VERSION ""

NS_ :

BS_:

BU_: GW LAS

BO_ 459 GW_1CB: 16 GW
 SG_ IBCU_RollingCounter_1CB : 51|4@0+ (1,0) [0|15] "" Vector__XXX
 SG_ IBCU_CRCCheck_1CB : 63|8@0+ (1,0) [0|255] "" Vector__XXX
 SG_ IBCU_CRCCheck_237 : 127|8@0+ (1,0) [0|255] "" Vector__XXX
 SG_ IBCU_RollingCounter_237 : 115|4@0+ (1,0) [0|15] "" Vector__XXX
 SG_ IBCU_BrakePedalApplied : 90|1@0+ (1,0) [0|1] ""  LAS

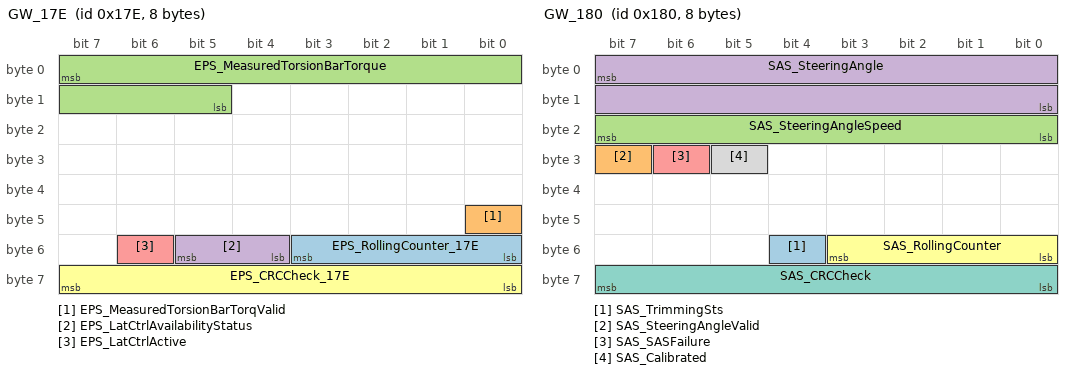
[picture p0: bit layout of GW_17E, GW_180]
BO_ 382 GW_17E: 8 GW
 SG_ EPS_RollingCounter_17E : 51|4@0+ (1,0) [0|15] ""  LAS
 SG_ EPS_MeasuredTorsionBarTorqValid : 40|1@0+ (1,0) [0|1] ""  LAS
 SG_ EPS_MeasuredTorsionBarTorque : 7|11@0+ (0.01,-10.23) [-10.23|10.23] "Nm"  LAS
 SG_ EPS_LatCtrlAvailabilityStatus : 53|2@0+ (1,0) [0|3] ""  LAS
 SG_ EPS_LatCtrlActive : 54|1@0+ (1,0) [0|1] ""  LAS
 SG_ EPS_CRCCheck_17E : 63|8@0+ (1,0) [0|255] ""  LAS

BO_ 384 GW_180: 8 GW
 SG_ SAS_TrimmingSts : 52|1@0+ (1,0) [0|1] ""  LAS
 SG_ SAS_SteeringAngleValid : 31|1@0+ (1,0) [0|1] ""  LAS
 SG_ SAS_SteeringAngleSpeed : 23|8@0+ (4,0) [0|1016] "deg/s"  LAS
 SG_ SAS_SteeringAngle : 7|16@0- (0.1,0) [-780|780] "degree"  LAS
 SG_ SAS_SASFailure : 30|1@0+ (1,0) [0|1] ""  LAS
 SG_ SAS_RollingCounter : 51|4@0+ (1,0) [0|15] ""  LAS
 SG_ SAS_CRCCheck : 63|8@0+ (1,0) [0|255] ""  LAS
 SG_ SAS_Calibrated : 29|1@0+ (1,0) [0|1] ""  LAS

BO_ 391 EPBi_187: 48 GW
 SG_ ESP_VehicleSpeedValid : 37|1@0+ (1,0) [0|1] ""  LAS
 SG_ ESP_VehicleSpeed : 36|13@0+ (0.05625,0) [0|360] "km/h"  LAS
 SG_ ESP_TCSFailStatus : 4|1@0+ (1,0) [0|1] ""  LAS
 SG_ ESP_RollingCounter_187 : 51|4@0+ (1,0) [0|15] ""  LAS
 SG_ ESP_ESPFunctionStatus : 1|1@0+ (1,0) [0|1] ""  LAS
 SG_ ESP_ESPActiveStatus : 0|1@0+ (1,0) [0|1] ""  LAS
 SG_ ESP_CRCCheck_187 : 63|8@0+ (1,0) [0|255] ""  LAS
 SG_ ESP_ABSFailStatus : 3|1@0+ (1,0) [0|1] ""  LAS

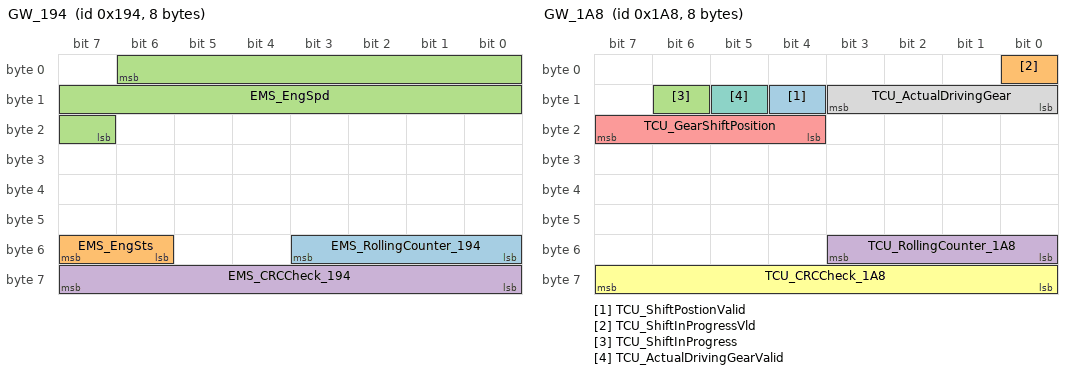
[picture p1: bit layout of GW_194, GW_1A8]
BO_ 404 GW_194: 8 GW
 SG_ EMS_RollingCounter_194 : 51|4@0+ (1,0) [0|15] ""  LAS
 SG_ EMS_EngSts : 55|2@0+ (1,0) [0|3] ""  LAS
 SG_ EMS_EngSpd : 6|16@0+ (0.25,0) [0|16383.5] "Rpm"  LAS
 SG_ EMS_CRCCheck_194 : 63|8@0+ (1,0) [0|255] ""  LAS

BO_ 422 GW_1A6: 8 GW
 SG_ PCU_PwrTrainSts : 55|2@0+ (1,0) [0|3] ""  LAS
 SG_ PCU_AccPedl : 47|8@0+ (0.392,0) [0|99.96] "pct"  LAS

BO_ 424 GW_1A8: 8 GW
 SG_ TCU_ShiftPostionValid : 12|1@0+ (1,0) [0|1] ""  LAS
 SG_ TCU_ShiftInProgressVld : 0|1@0+ (1,0) [0|1] ""  LAS
 SG_ TCU_ShiftInProgress : 14|1@0+ (1,0) [0|1] ""  LAS
 SG_ TCU_RollingCounter_1A8 : 51|4@0+ (1,0) [0|15] ""  LAS
 SG_ TCU_GearShiftPosition : 23|4@0+ (1,0) [0|15] ""  LAS
 SG_ TCU_CRCCheck_1A8 : 63|8@0+ (1,0) [0|255] ""  LAS
 SG_ TCU_ActualDrivingGearValid : 13|1@0+ (1,0) [0|1] ""  LAS
 SG_ TCU_ActualDrivingGear : 11|4@0+ (1,0) [0|15] ""  LAS

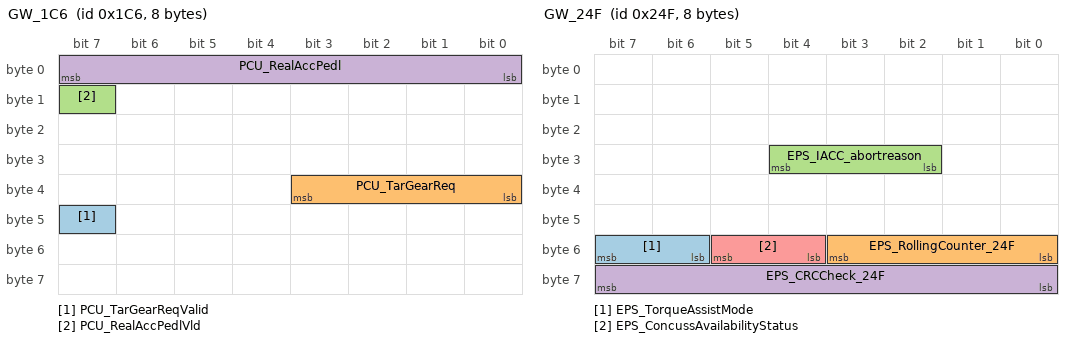
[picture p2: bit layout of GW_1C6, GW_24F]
BO_ 454 GW_1C6: 8 GW
 SG_ PCU_TarGearReqValid : 47|1@0+ (1,0) [0|1] ""  LAS
 SG_ PCU_TarGearReq : 35|4@0+ (1,0) [0|15] ""  LAS
 SG_ PCU_RealAccPedlVld : 15|1@0+ (1,0) [0|1] ""  LAS
 SG_ PCU_RealAccPedl : 7|8@0+ (0.392,0) [0|99.96] "%"  LAS

BO_ 518 EPBi_206: 48 GW
 SG_ ESP_CRCCheck_277 : 319|8@0+ (1,0) [0|255] "" Vector__XXX
 SG_ ESP_RollingCounter_277 : 307|4@0+ (1,0) [0|15] "" Vector__XXX
 SG_ Wheel_Speed_RR_Valid_Data : 71|1@0+ (1,0) [0|1] ""  LAS
 SG_ Wheel_Speed_RR_Pulse : 231|8@0+ (1,0) [0|254] ""  LAS
 SG_ Wheel_Speed_RR_Direction : 70|2@0+ (1,0) [0|3] ""  LAS
 SG_ Wheel_Speed_RR_Data : 68|13@0+ (0.05625,0) [0|360] "km/h"  LAS
 SG_ Wheel_Speed_RL_Valid_Data : 87|1@0+ (1,0) [0|1] ""  LAS
 SG_ Wheel_Speed_RL_Pulse : 239|8@0+ (1,0) [0|254] ""  LAS
 SG_ Wheel_Speed_RL_Direction : 86|2@0+ (1,0) [0|3] ""  LAS
 SG_ Wheel_Speed_RL_Data : 84|13@0+ (0.05625,0) [0|360] "km/h"  LAS
 SG_ Wheel_Speed_FR_Valid_Data : 7|1@0+ (1,0) [0|1] ""  LAS
 SG_ Wheel_Speed_FR_Pulse : 223|8@0+ (1,0) [0|254] ""  LAS
 SG_ Wheel_Speed_FR_Direction : 6|2@0+ (1,0) [0|3] ""  LAS
 SG_ Wheel_Speed_FR_Data : 4|13@0+ (0.05625,0) [0|360] "km/h"  LAS
 SG_ Wheel_Speed_FL_Valid_Data : 23|1@0+ (1,0) [0|1] ""  LAS
 SG_ Wheel_Speed_FL_Pulse : 215|8@0+ (1,0) [0|254] ""  LAS
 SG_ Wheel_Speed_FL_Direction : 22|2@0+ (1,0) [0|3] ""  LAS
 SG_ Wheel_Speed_FL_Data : 20|13@0+ (0.05625,0) [0|360] "km/h"  LAS
 SG_ ESP_YawRateValid : 375|1@0+ (1,0) [0|1] ""  LAS
 SG_ ESP_YawRate : 357|14@0+ (0.01,-81.91) [-81.91|81.91] "degree/s"  LAS
 SG_ ESP_VehicleStandstill : 267|1@0+ (1,0) [0|1] ""  LAS
 SG_ ESP_VDCActive : 266|1@0+ (1,0) [0|1] ""  LAS
 SG_ ESP_TCSActive : 265|1@0+ (1,0) [0|1] ""  LAS
 SG_ ESP_RollingCounter_278 : 371|4@0+ (1,0) [0|15] ""  LAS
 SG_ ESP_RollingCounter_258 : 243|4@0+ (1,0) [0|15] ""  LAS
 SG_ ESP_RollingCounter_208 : 115|4@0+ (1,0) [0|15] ""  LAS
 SG_ ESP_RollingCounter_206 : 51|4@0+ (1,0) [0|15] ""  LAS
 SG_ ESP_PrefillAvailable : 259|1@0+ (1,0) [0|1] ""  LAS
 SG_ ESP_PrefillActive : 260|1@0+ (1,0) [0|1] ""  LAS
 SG_ ESP_OnlyABSActive : 264|1@0+ (1,0) [0|1] ""  LAS
 SG_ ESP_MasCylBrakePressureValid : 199|1@0+ (1,0) [0|1] ""  LAS
 SG_ ESP_MasCylBrakePressure : 195|12@0+ (0.1,0) [0|250] "Bar"  LAS
 SG_ ESP_LongAccel : 351|10@0+ (0.03125,-16) [-16|15.90625] "m/s2"  LAS
 SG_ ESP_LatAccel : 343|8@0+ (0.1,-12.7) [-12.7|12.7] "m/s2"  LAS
 SG_ ESP_HDC_STATUS : 274|2@0+ (1,0) [0|3] ""  LAS
 SG_ ESP_CRCCheck_278 : 383|8@0+ (1,0) [0|255] ""  LAS
 SG_ ESP_CRCCheck_258 : 255|8@0+ (1,0) [0|255] ""  LAS
 SG_ ESP_CRCCheck_208 : 127|8@0+ (1,0) [0|255] ""  LAS
 SG_ ESP_CRCCheck_206 : 63|8@0+ (1,0) [0|255] ""  LAS
 SG_ ESP_BrakeForce : 263|1@0+ (1,0) [0|1] ""  LAS
 SG_ ESP_AWBavailable : 271|1@0+ (1,0) [0|1] ""  LAS
 SG_ ESP_AWBactive : 256|1@0+ (1,0) [0|1] ""  LAS
 SG_ ESP_AEBdecActive : 257|1@0+ (1,0) [0|1] ""  LAS
 SG_ ESP_AEBAvailable : 258|1@0+ (1,0) [0|1] ""  LAS
 SG_ ESP_ABAavailable : 261|1@0+ (1,0) [0|1] ""  LAS
 SG_ ESP_ABAactive : 262|1@0+ (1,0) [0|1] ""  LAS

BO_ 583 APA_247: 32 GW
 SG_ APA_APAOnOff : 6|1@0+ (1,0) [0|1] ""  LAS

BO_ 591 GW_24F: 8 GW
 SG_ EPS_TorqueAssistMode : 55|2@0+ (1,0) [0|3] ""  LAS
 SG_ EPS_RollingCounter_24F : 51|4@0+ (1,0) [0|15] ""  LAS
 SG_ EPS_IACC_abortreason : 28|3@0+ (1,0) [0|7] ""  LAS
 SG_ EPS_CRCCheck_24F : 63|8@0+ (1,0) [0|255] ""  LAS
 SG_ EPS_ConcussAvailabilityStatus : 53|2@0+ (1,0) [0|3] ""  LAS

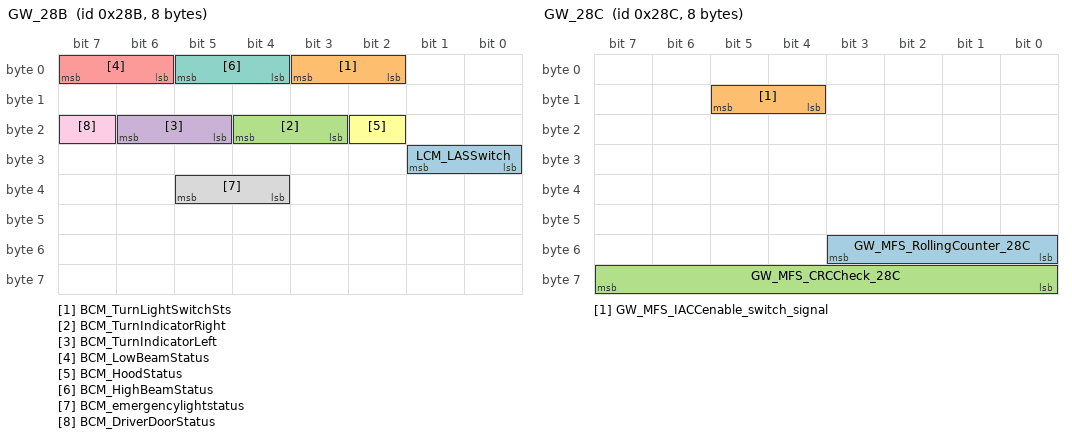
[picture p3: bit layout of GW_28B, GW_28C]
BO_ 651 GW_28B: 8 GW
 SG_ LCM_LASSwitch : 25|2@0+ (1,0) [0|3] ""  LAS
 SG_ BCM_TurnLightSwitchSts : 3|2@0+ (1,0) [0|3] ""  LAS
 SG_ BCM_TurnIndicatorRight : 20|2@0+ (1,0) [0|3] ""  LAS
 SG_ BCM_TurnIndicatorLeft : 22|2@0+ (1,0) [0|3] ""  LAS
 SG_ BCM_LowBeamStatus : 7|2@0+ (1,0) [0|3] ""  LAS
 SG_ BCM_HoodStatus : 18|1@0+ (1,0) [0|1] ""  LAS
 SG_ BCM_HighBeamStatus : 5|2@0+ (1,0) [0|3] ""  LAS
 SG_ BCM_emergencylightstatus : 37|2@0+ (1,0) [0|3] ""  LAS
 SG_ BCM_DriverDoorStatus : 23|1@0+ (1,0) [0|1] ""  LAS

BO_ 652 GW_28C: 8 GW
 SG_ GW_MFS_RollingCounter_28C : 51|4@0+ (1,0) [0|15] ""  LAS
 SG_ GW_MFS_IACCenable_switch_signal : 13|2@0+ (1,0) [0|3] ""  LAS
 SG_ GW_MFS_CRCCheck_28C : 63|8@0+ (1,0) [0|255] ""  LAS

BO_ 676 LCDAR_2A4: 64 GW
 SG_ LCDAR_RollingCounter_2AF : 51|4@0+ (1,0) [0|15] ""  LAS
 SG_ LCDAR_Left_ELK_oAlert : 29|2@0+ (1,0) [0|3] ""  LAS
 SG_ LCDAR_ELK_oStatus : 27|2@0+ (1,0) [0|3] ""  LAS
 SG_ LCDAR_ELK_oAlert : 25|2@0+ (1,0) [0|3] ""  LAS
 SG_ LCDAR_CRCCheck_2AF : 63|8@0+ (1,0) [0|255] ""  LAS

BO_ 832 GW_340: 8 GW
 SG_ AC_FrBlowType : 2|3@0+ (1,0) [0|7] ""  LAS

BO_ 866 GW_362: 8 GW
 SG_ PCU_DrvMod : 21|3@0+ (1,0) [0|7] ""  LAS

BO_ 870 GW_366: 8 GW
 SG_ AC_EnvironmentalTempVD : 8|1@0+ (1,0) [0|1] ""  LAS
 SG_ AC_EnvironmentalTemp : 23|8@0+ (0.5,-40) [-40|87] "degreeC"  LAS

BO_ 903 GW_387: 8 GW
 SG_ BCM_RainfallLevel : 19|4@0+ (1,0) [0|15] ""  LAS
 SG_ BCM_FrontWiperStatus : 25|2@0+ (1,0) [0|3] ""  LAS

BO_ 912 GW_390: 8 GW
 SG_ BCM_SOH_LifePercent : 15|8@0+ (1,0) [0|100] "%"  LAS
 SG_ BCM_PMSLevel : 5|3@0+ (1,0) [0|7] ""  LAS

BO_ 916 GW_394: 8 GW
 SG_ HU_TLAEnable : 9|2@0+ (1,0) [0|3] ""  LAS
 SG_ HU_ELKEnable : 1|2@0+ (1,0) [0|3] ""  LAS

BO_ 922 LAS_39A: 32 LAS
 SG_ LAS_TSRWarningSign : 83|4@0+ (1,0) [0|15] "" Vector__XXX
 SG_ LAS_TSRStatus : 26|3@0+ (1,0) [0|7] "" Vector__XXX
 SG_ LAS_TSRRightLaneStatus : 55|3@0+ (1,0) [0|7] "" Vector__XXX
 SG_ LAS_TSRRightLaneSpdLimit : 143|8@0+ (1,0) [0|255] "" Vector__XXX
 SG_ LAS_TSRProhibitionSign : 66|5@0+ (1,0) [0|31] "" Vector__XXX
 SG_ LAS_TSRMandatorySign : 70|4@0+ (1,0) [0|15] "" Vector__XXX
 SG_ LAS_TSRLeftLaneStatus : 47|3@0+ (1,0) [0|7] "" Vector__XXX
 SG_ LAS_TSRLeftLaneSpdLimit : 135|8@0+ (1,0) [0|255] "" Vector__XXX
 SG_ LAS_TSRHostSpdLimitUnits : 41|2@0+ (1,0) [0|3] "" Vector__XXX
 SG_ LAS_TSRHostSpdLimit : 39|8@0+ (1,0) [0|255] "" Vector__XXX
 SG_ LAS_TSREnable : 30|1@0+ (1,0) [0|1] "" Vector__XXX
 SG_ LAS_TLAWarninglevel : 197|2@0+ (1,0) [0|3] "" Vector__XXX
 SG_ LAS_TLAStopLine_HostLane : 111|8@0+ (1,0) [0|255] "" Vector__XXX
 SG_ LAS_TLAStatus : 193|2@0+ (1,0) [0|3] "" Vector__XXX
 SG_ LAS_TLAObjectType_RightLane : 239|3@0+ (1,0) [0|7] "" Vector__XXX
 SG_ LAS_TLAObjectType_LeftLane : 219|3@0+ (1,0) [0|7] "" Vector__XXX
 SG_ LAS_TLAObjectType_HostLane : 212|3@0+ (1,0) [0|7] "" Vector__XXX
 SG_ LAS_TLAObjectStatus_RightLane : 247|2@0+ (1,0) [0|3] "" Vector__XXX
 SG_ LAS_TLAObjectStatus_LeftLane : 245|2@0+ (1,0) [0|3] "" Vector__XXX
 SG_ LAS_TLAObjectStatus_HostLane : 199|2@0+ (1,0) [0|3] "" Vector__XXX
 SG_ LAS_TLAObjectDetection_RightLane : 227|1@0+ (1,0) [0|1] "" Vector__XXX
 SG_ LAS_TLAObjectDetection_LeftLane : 223|1@0+ (1,0) [0|1] "" Vector__XXX
 SG_ LAS_TLAObjectDetection_HostLane : 200|1@0+ (1,0) [0|1] "" Vector__XXX
 SG_ LAS_TLAObjectColour_RightLane : 225|2@0+ (1,0) [0|3] "" Vector__XXX
 SG_ LAS_TLAObjectColour_LeftLane : 221|2@0+ (1,0) [0|3] "" Vector__XXX
 SG_ LAS_TLAObjectColour_HostLane : 204|2@0+ (1,0) [0|3] "" Vector__XXX
 SG_ LAS_TLAEnable : 194|1@0+ (1,0) [0|1] "" Vector__XXX
 SG_ LAS_TLADistance_HostLane : 103|8@0+ (1,0) [0|255] "" Vector__XXX
 SG_ LAS_TLACountDownTime_HostLane : 94|7@0+ (1,0) [0|127] "" Vector__XXX
 SG_ LAS_TLAArrowDirection_RightLane : 236|3@0+ (1,0) [0|7] "" Vector__XXX
 SG_ LAS_TLAArrowDirection_LeftLane : 216|3@0+ (1,0) [0|7] "" Vector__XXX
 SG_ LAS_TLAArrowDirection_HostLane : 215|3@0+ (1,0) [0|7] "" Vector__XXX
 SG_ LAS_RollingCounter_3D4 : 115|4@0+ (1,0) [0|15] "" Vector__XXX
 SG_ LAS_RollingCounter_3C0 : 179|4@0+ (1,0) [0|15] "" Vector__XXX
 SG_ LAS_RollingCounter_37D : 243|4@0+ (1,0) [0|15] "" Vector__XXX
 SG_ LAS_RollingCounter_332 : 51|4@0+ (1,0) [0|15] "" Vector__XXX
 SG_ LAS_OverspeedWarningOffset : 14|5@0+ (1,-10) [-10|10] "km/h" Vector__XXX
 SG_ LAS_OverspeedWarningEnableStatus : 15|1@0+ (1,0) [0|1] "" Vector__XXX
 SG_ LAS_OverspeedVisualWarning : 5|1@0+ (1,0) [0|1] "" Vector__XXX
 SG_ LAS_OverspeedSoundWarningEnSt : 27|1@0+ (1,0) [0|1] "" Vector__XXX
 SG_ LAS_OverspeedSoundWarning : 2|1@0+ (1,0) [0|1] "" Vector__XXX
 SG_ LAS_HMAStatus : 44|2@0+ (1,0) [0|3] "" Vector__XXX
 SG_ LAS_HMALightDistribution : 8|1@0+ (1,0) [0|1] "" Vector__XXX
 SG_ LAS_HMAEnableStatus : 22|1@0+ (1,0) [0|1] "" Vector__XXX
 SG_ LAS_FrontCameraFailureStatus : 17|2@0+ (1,0) [0|3] "" Vector__XXX
 SG_ LAS_FrontCameraCalibrationStatus : 20|2@0+ (1,0) [0|3] "" Vector__XXX
 SG_ LAS_CRCCheck_3D4 : 127|8@0+ (1,0) [0|255] "" Vector__XXX
 SG_ LAS_CRCCheck_3C0 : 191|8@0+ (1,0) [0|255] "" Vector__XXX
 SG_ LAS_CRCCheck_37D : 255|8@0+ (1,0) [0|255] "" Vector__XXX
 SG_ LAS_CRCCheck_332 : 63|8@0+ (1,0) [0|255] "" Vector__XXX

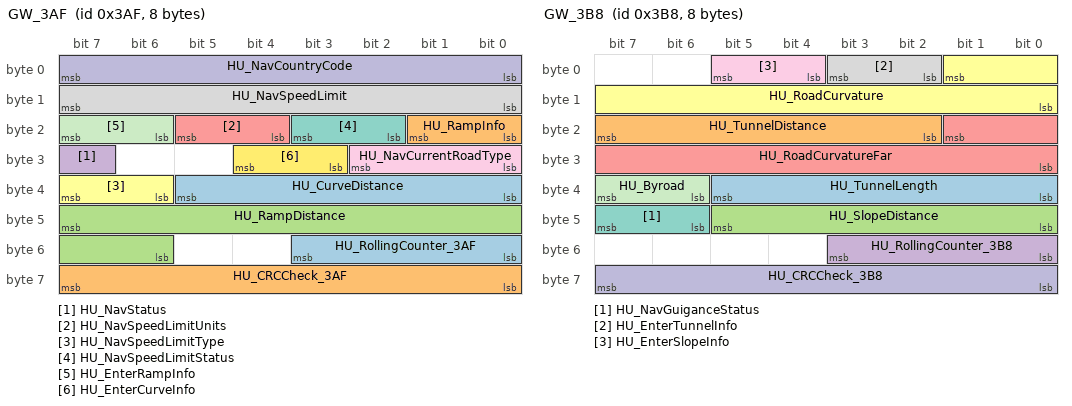
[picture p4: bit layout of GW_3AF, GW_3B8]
BO_ 943 GW_3AF: 8 GW
 SG_ HU_RollingCounter_3AF : 51|4@0+ (1,0) [0|15] ""  LAS
 SG_ HU_RampInfo : 17|2@0+ (1,0) [0|3] ""  LAS
 SG_ HU_RampDistance : 47|10@0+ (10,0) [0|3000] "m"  LAS
 SG_ HU_NavStatus : 31|1@0+ (1,0) [0|1] ""  LAS
 SG_ HU_NavSpeedLimitUnits : 21|2@0+ (1,0) [0|3] ""  LAS
 SG_ HU_NavSpeedLimitType : 39|2@0+ (1,0) [0|3] ""  LAS
 SG_ HU_NavSpeedLimitStatus : 19|2@0+ (1,0) [0|3] ""  LAS
 SG_ HU_NavSpeedLimit : 15|8@0+ (1,0) [0|255] ""  LAS
 SG_ HU_NavCurrentRoadType : 26|3@0+ (1,0) [0|7] ""  LAS
 SG_ HU_NavCountryCode : 7|8@0+ (1,0) [0|255] ""  LAS
 SG_ HU_EnterRampInfo : 23|2@0+ (1,0) [0|3] ""  LAS
 SG_ HU_EnterCurveInfo : 28|2@0+ (1,0) [0|3] ""  LAS
 SG_ HU_CurveDistance : 37|6@0+ (10,0) [0|600] "m"  LAS
 SG_ HU_CRCCheck_3AF : 63|8@0+ (1,0) [0|255] ""  LAS

BO_ 952 GW_3B8: 8 GW
 SG_ HU_TunnelLength : 37|6@0+ (1,0) [0|63] "m"  LAS
 SG_ HU_TunnelDistance : 23|6@0+ (10,0) [0|600] "m"  LAS
 SG_ HU_SlopeDistance : 45|6@0+ (10,0) [0|600] "m"  LAS
 SG_ HU_RollingCounter_3B8 : 51|4@0+ (1,0) [0|15] ""  LAS
 SG_ HU_RoadCurvatureFar : 17|10@0+ (1,0) [0|1023] ""  LAS
 SG_ HU_RoadCurvature : 1|10@0+ (1,0) [0|1023] ""  LAS
 SG_ HU_NavGuiganceStatus : 47|2@0+ (1,0) [0|3] ""  LAS
 SG_ HU_EnterTunnelInfo : 3|2@0+ (1,0) [0|3] ""  LAS
 SG_ HU_EnterSlopeInfo : 5|2@0+ (1,0) [0|3] ""  LAS
 SG_ HU_CRCCheck_3B8 : 63|8@0+ (1,0) [0|255] ""  LAS
 SG_ HU_Byroad : 39|2@0+ (1,0) [0|3] ""  LAS

BO_ 955 GW_3BB: 8 GW
 SG_ HU_SpeedLimitDistance : 5|6@0+ (10,0) [0|600] "m"  LAS

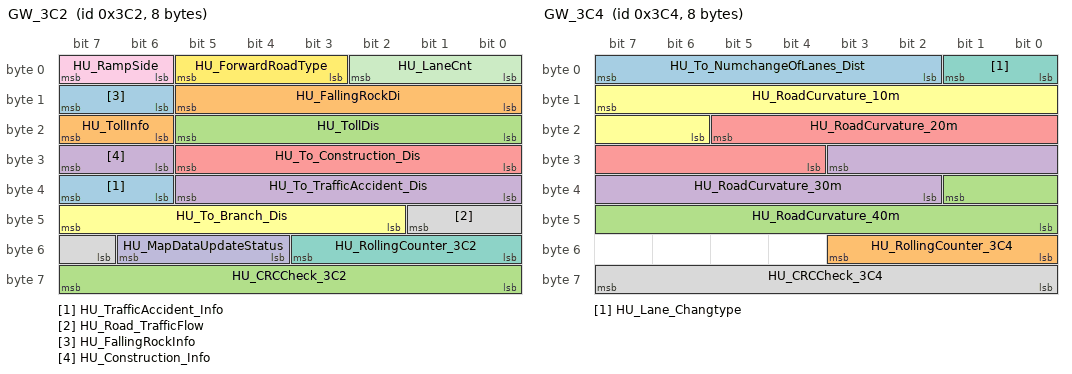
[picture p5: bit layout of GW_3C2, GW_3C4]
BO_ 962 GW_3C2: 8 GW
 SG_ HU_TrafficAccident_Info : 39|2@0+ (1,0) [0|3] ""  LAS
 SG_ HU_TollInfo : 23|2@0+ (1,0) [0|3] ""  LAS
 SG_ HU_TollDis : 21|6@0+ (10,0) [0|600] "m"  LAS
 SG_ HU_To_TrafficAccident_Dis : 37|6@0+ (10,0) [0|600] "m"  LAS
 SG_ HU_To_Construction_Dis : 29|6@0+ (10,0) [0|600] "m"  LAS
 SG_ HU_To_Branch_Dis : 47|6@0+ (10,0) [0|600] "m"  LAS
 SG_ HU_RollingCounter_3C2 : 51|4@0+ (1,0) [0|15] ""  LAS
 SG_ HU_Road_TrafficFlow : 41|3@0+ (1,0) [0|7] ""  LAS
 SG_ HU_RampSide : 7|2@0+ (1,0) [0|3] ""  LAS
 SG_ HU_MapDataUpdateStatus : 54|3@0+ (1,0) [0|7] ""  LAS
 SG_ HU_LaneCnt : 2|3@0+ (1,0) [0|7] ""  LAS
 SG_ HU_ForwardRoadType : 5|3@0+ (1,0) [0|7] ""  LAS
 SG_ HU_FallingRockInfo : 15|2@0+ (1,0) [0|3] ""  LAS
 SG_ HU_FallingRockDi : 13|6@0+ (10,0) [0|600] "m"  LAS
 SG_ HU_CRCCheck_3C2 : 63|8@0+ (1,0) [0|255] ""  LAS
 SG_ HU_Construction_Info : 31|2@0+ (1,0) [0|3] ""  LAS

BO_ 964 GW_3C4: 8 GW
 SG_ HU_To_NumchangeOfLanes_Dist : 7|6@0+ (10,0) [0|600] "m"  LAS
 SG_ HU_RollingCounter_3C4 : 51|4@0+ (1,0) [0|15] ""  LAS
 SG_ HU_RoadCurvature_40m : 33|10@0+ (1,0) [0|1023] "1/m"  LAS
 SG_ HU_RoadCurvature_30m : 27|10@0+ (1,0) [0|1023] "1/m"  LAS
 SG_ HU_RoadCurvature_20m : 21|10@0+ (1,0) [0|1023] "1/m"  LAS
 SG_ HU_RoadCurvature_10m : 15|10@0+ (1,0) [0|1023] "1/m"  LAS
 SG_ HU_Lane_Changtype : 1|2@0+ (1,0) [0|3] ""  LAS
 SG_ HU_CRCCheck_3C4 : 63|8@0+ (1,0) [0|255] ""  LAS

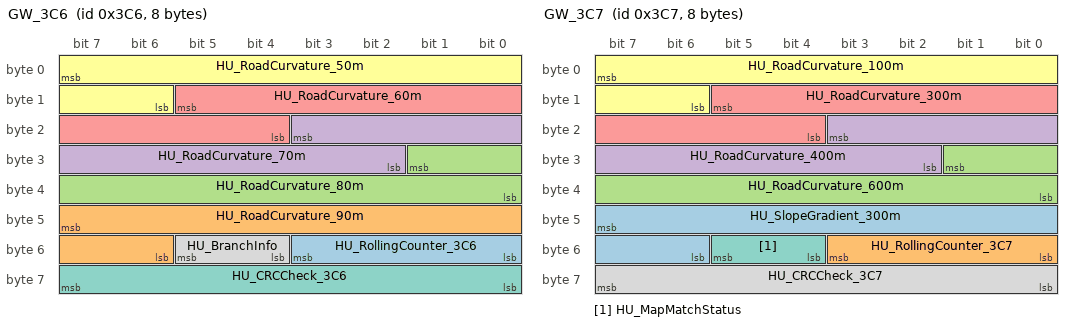
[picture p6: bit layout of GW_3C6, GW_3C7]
BO_ 966 GW_3C6: 8 GW
 SG_ HU_RollingCounter_3C6 : 51|4@0+ (1,0) [0|15] ""  LAS
 SG_ HU_RoadCurvature_90m : 47|10@0+ (1,0) [0|1023] "1/m"  LAS
 SG_ HU_RoadCurvature_80m : 25|10@0+ (1,0) [0|1023] "1/m"  LAS
 SG_ HU_RoadCurvature_70m : 19|10@0+ (1,0) [0|1023] "1/m"  LAS
 SG_ HU_RoadCurvature_60m : 13|10@0+ (1,0) [0|1023] "1/m"  LAS
 SG_ HU_RoadCurvature_50m : 7|10@0+ (1,0) [0|1023] "1/m"  LAS
 SG_ HU_CRCCheck_3C6 : 63|8@0+ (1,0) [0|255] ""  LAS
 SG_ HU_BranchInfo : 53|2@0+ (1,0) [0|3] ""  LAS

BO_ 967 GW_3C7: 8 GW
 SG_ HU_SlopeGradient_300m : 47|10@0+ (0.1,-51.1) [-51.1|51.1] "%"  LAS
 SG_ HU_RollingCounter_3C7 : 51|4@0+ (1,0) [0|15] ""  LAS
 SG_ HU_RoadCurvature_600m : 25|10@0+ (1,0) [0|1023] "1/m"  LAS
 SG_ HU_RoadCurvature_400m : 19|10@0+ (1,0) [0|1023] "1/m"  LAS
 SG_ HU_RoadCurvature_300m : 13|10@0+ (1,0) [0|1023] "1/m"  LAS
 SG_ HU_RoadCurvature_100m : 7|10@0+ (1,0) [0|1023] "1/m"  LAS
 SG_ HU_MapMatchStatus : 53|2@0+ (1,0) [0|3] ""  LAS
 SG_ HU_CRCCheck_3C7 : 63|8@0+ (1,0) [0|255] ""  LAS

BO_ 999 GW_3E7: 8 GW
 SG_ BCM_T_BATT : 39|8@0+ (1,-40) [-40|105] "C"  LAS
 SG_ BCM_Status_Temp : 51|2@0+ (1,0) [0|3] ""  LAS

BO_ 1000 GW_3E8: 8 GW
 SG_ BCM_SOF_Q_STATE : 51|2@0+ (1,0) [0|3] ""  LAS
 SG_ BCM_SOF_Q : 15|8@0+ (0.5,0) [0|127] "Ah"  LAS

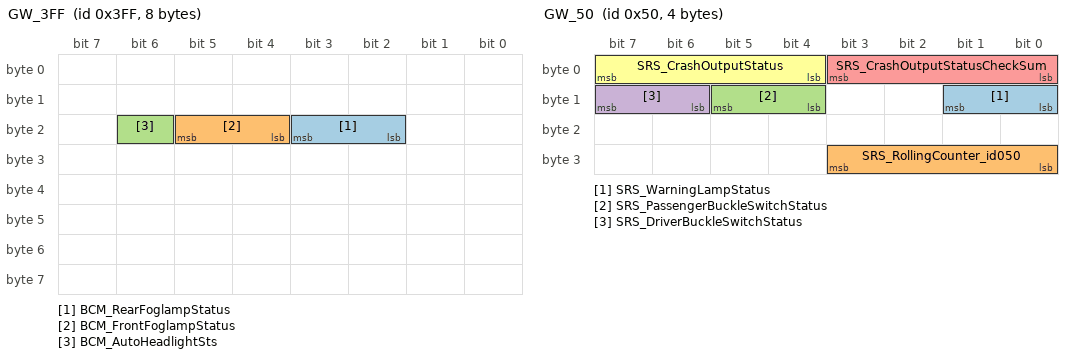
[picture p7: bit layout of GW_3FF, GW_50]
BO_ 1023 GW_3FF: 8 GW
 SG_ BCM_RearFoglampStatus : 19|2@0+ (1,0) [0|3] ""  LAS
 SG_ BCM_FrontFoglampStatus : 21|2@0+ (1,0) [0|3] ""  LAS
 SG_ BCM_AutoHeadlightSts : 22|1@0+ (1,0) [0|1] ""  LAS

BO_ 80 GW_50: 4 GW
 SG_ SRS_WarningLampStatus : 9|2@0+ (1,0) [0|3] ""  LAS
 SG_ SRS_RollingCounter_id050 : 27|4@0+ (1,0) [0|15] ""  LAS
 SG_ SRS_PassengerBuckleSwitchStatus : 13|2@0+ (1,0) [0|3] ""  LAS
 SG_ SRS_DriverBuckleSwitchStatus : 15|2@0+ (1,0) [0|3] ""  LAS
 SG_ SRS_CrashOutputStatusCheckSum : 3|4@0+ (1,0) [0|15] ""  LAS
 SG_ SRS_CrashOutputStatus : 7|4@0+ (1,0) [0|15] ""  LAS

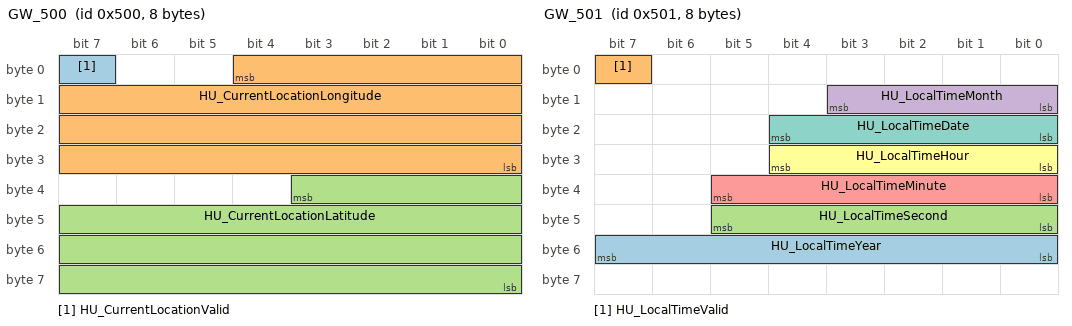
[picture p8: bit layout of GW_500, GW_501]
BO_ 1280 GW_500: 8 GW
 SG_ HU_CurrentLocationValid : 7|1@0+ (1,0) [0|1] ""  LAS
 SG_ HU_CurrentLocationLongitude : 4|29@0+ (1E-006,-268.435455) [-180|180] "degree"  LAS
 SG_ HU_CurrentLocationLatitude : 35|28@0+ (1E-006,-134.217727) [-90|90] "degree"  LAS

BO_ 1281 GW_501: 8 GW
 SG_ HU_LocalTimeYear : 55|8@0+ (1,2013) [2013|2268] "year"  LAS
 SG_ HU_LocalTimeValid : 7|1@0+ (1,0) [0|1] ""  LAS
 SG_ HU_LocalTimeSecond : 45|6@0+ (1,0) [0|59] "second"  LAS
 SG_ HU_LocalTimeMonth : 11|4@0+ (1,0) [1|12] "month"  LAS
 SG_ HU_LocalTimeMinute : 37|6@0+ (1,0) [0|59] "minute"  LAS
 SG_ HU_LocalTimeHour : 28|5@0+ (1,0) [0|23] "hour"  LAS
 SG_ HU_LocalTimeDate : 20|5@0+ (1,0) [1|31] "day"  LAS

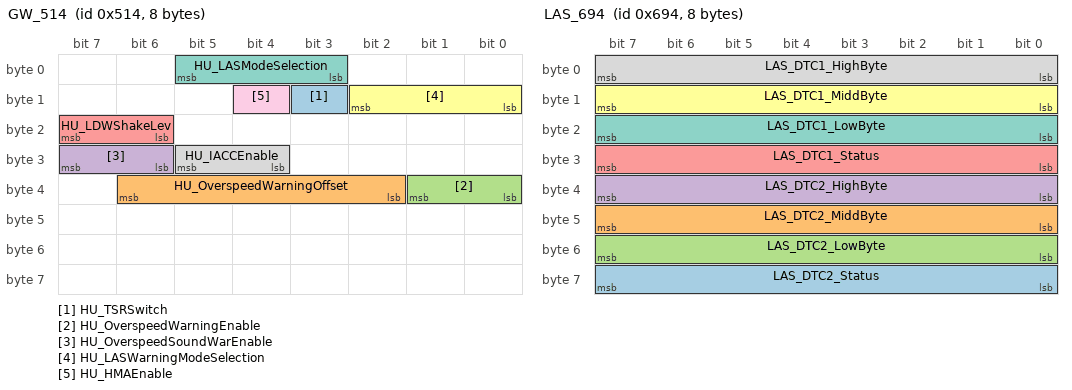
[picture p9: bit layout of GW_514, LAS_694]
BO_ 1300 GW_514: 8 GW
 SG_ HU_TSRSwitch : 11|1@0+ (1,0) [0|1] ""  LAS
 SG_ HU_OverspeedWarningOffset : 38|5@0+ (1,-10) [-10|10] ""  LAS
 SG_ HU_OverspeedWarningEnable : 33|2@0+ (1,0) [0|3] ""  LAS
 SG_ HU_OverspeedSoundWarEnable : 31|2@0+ (1,0) [0|3] ""  LAS
 SG_ HU_LDWShakeLev : 23|2@0+ (1,0) [0|3] ""  LAS
 SG_ HU_LASWarningModeSelection : 10|3@0+ (1,0) [0|7] ""  LAS
 SG_ HU_LASModeSelection : 5|3@0+ (1,0) [0|7] ""  LAS
 SG_ HU_IACCEnable : 29|2@0+ (1,0) [0|3] ""  LAS
 SG_ HU_HMAEnable : 12|1@0+ (1,0) [0|1] ""  LAS

BO_ 1328 GW_530: 8 GW
 SG_ IP_TotalOdometer : 23|24@0+ (0.1,0) [0|999999] "Km"  LAS

BO_ 1684 LAS_694: 8 LAS
 SG_ LAS_DTC2_Status : 63|8@0+ (1,0) [0|255] "" Vector__XXX
 SG_ LAS_DTC2_MiddByte : 47|8@0+ (1,0) [0|255] "" Vector__XXX
 SG_ LAS_DTC2_LowByte : 55|8@0+ (1,0) [0|255] "" Vector__XXX
 SG_ LAS_DTC2_HighByte : 39|8@0+ (1,0) [0|255] "" Vector__XXX
 SG_ LAS_DTC1_Status : 31|8@0+ (1,0) [0|255] "" Vector__XXX
 SG_ LAS_DTC1_MiddByte : 15|8@0+ (1,0) [0|255] "" Vector__XXX
 SG_ LAS_DTC1_LowByte : 23|8@0+ (1,0) [0|255] "" Vector__XXX
 SG_ LAS_DTC1_HighByte : 7|8@0+ (1,0) [0|255] "" Vector__XXX

BO_ 1882 LAS_75A: 64 Vector__XXX

BO_ 1899 LAS_76B: 8 Vector__XXX

CM_ BO_ 459 " ";
CM_ BO_ 382 "L2_EPSCAN , L2_PCAN ";
CM_ SG_ 391 ESP_RollingCounter_187 "AT/DCT ";
CM_ SG_ 391 ESP_CRCCheck_187 "AT/DCT ";
CM_ BO_ 404 " ";
CM_ BO_ 422 " ";
CM_ BO_ 424 " ";
CM_ SG_ 424 TCU_RollingCounter_1A8 "AT/DCT
rollingcounter ";
CM_ SG_ 424 TCU_GearShiftPosition "TCU receives driver demands gear from ESL and make decisition of actual drive mode based on current vehicle/transmission status.
PCU receives this signals to understand actual drive mode and estimate target gear ";
CM_ BO_ 454 " ";
CM_ BO_ 518 "Combined 206,208,23B,258,277,278 ";
CM_ SG_ 518 Wheel_Speed_RR_Pulse "All4wheelpulsesignalsaresentbyABSwithoutfiltering.Theriseedgeandfalledgearebothcountedinit, thewheelpulsemustbesequentialintheway";
CM_ SG_ 518 Wheel_Speed_RL_Pulse "All4wheelpulsesignalsaresentbyABSwithoutfiltering.Theriseedgeandfalledgearebothcountedinit, thewheelpulsemustbesequentialintheway";
CM_ SG_ 518 Wheel_Speed_FR_Pulse "All4wheelpulsesignalsaresentbyABSwithoutfiltering.Theriseedgeandfalledgearebothcountedinit, thewheelpulsemustbesequentialintheway";
CM_ SG_ 518 Wheel_Speed_FL_Pulse "All4wheelpulsesignalsaresentbyABSwithoutfiltering.Theriseedgeandfalledgearebothcountedinit, thewheelpulsemustbesequentialintheway";
CM_ SG_ 518 ESP_RollingCounter_278 "rollingcounter ";
CM_ SG_ 518 ESP_RollingCounter_258 "258 ";
CM_ SG_ 518 ESP_RollingCounter_208 "rollingcounter ";
CM_ SG_ 518 ESP_RollingCounter_206 "rollingcounter ";
CM_ SG_ 518 ESP_MasCylBrakePressureValid "258 ";
CM_ SG_ 518 ESP_CRCCheck_258 "258 ";
CM_ BO_ 583 " ";
CM_ BO_ 651 " ";
CM_ BO_ 652 "MFS_LIN_2 ";
CM_ SG_ 676 LCDAR_RollingCounter_2AF "Rolling counter ";
CM_ BO_ 832 " ";
CM_ BO_ 866 " ";
CM_ BO_ 870 " ";
CM_ BO_ 903 " ";
CM_ BO_ 912 " ";
CM_ BO_ 916 " ";
CM_ SG_ 922 LAS_RollingCounter_3D4 "Rolling counter ";
CM_ SG_ 922 LAS_RollingCounter_3C0 "Rolling counter ";
CM_ SG_ 922 LAS_RollingCounter_37D "Rolling counter ";
CM_ SG_ 922 LAS_RollingCounter_332 "Rolling counter ";
CM_ BO_ 943 " ";
CM_ BO_ 952 " ";
CM_ BO_ 955 " ";
CM_ BO_ 962 " ";
CM_ BO_ 964 " ";
CM_ BO_ 966 " ";
CM_ BO_ 967 " ";
CM_ BO_ 999 " ";
CM_ BO_ 1000 " ";
CM_ BO_ 1023 " ";
CM_ SG_ 80 SRS_PassengerBuckleSwitchStatus "For PDM is configured projects:
(if PDM is configured£¬ logical detection with PDM is required)
0x0= [Buckled] or [Unbuckled and passenger not occupied]
0x1= [Unbuckle and passenger occupied]
0x2= Not Used
0x3= Not Used ";
CM_ BO_ 1280 " ";
CM_ BO_ 1281 " ";
CM_ BO_ 1300 " ";
CM_ BO_ 1328 " ";
CM_ BO_ 1684 " ";
BA_DEF_  "BusType" STRING ;
BA_DEF_ SG_  "GenSigSendType" ENUM  "Cyclic","OnWrite","OnWriteWithRepetition","OnChange","OnChangeWithRepetition","IfActive","IfActiveWithRepetition","NoSigSendType","NotUsed","NotUsed","NotUsed","NotUsed","NotUsed";
BA_DEF_ SG_  "GenSigCycleTime" INT 0 0;
BA_DEF_ SG_  "GenSigInvalidValue" STRING ;
BA_DEF_ SG_  "GenSigStartValue" INT 0 0;
BA_DEF_ BO_  "VFrameFormat" ENUM  "StandardCAN","ExtendedCAN","reserved","reserved","reserved","reserved","reserved","reserved","reserved","reserved","reserved","reserved","reserved","reserved","StandardCAN_FD","ExtendedCAN_FD";
BA_DEF_ BO_  "CANFD_BRS" ENUM  "0","1";
BA_DEF_ BO_  "GenMsgCycleTime" INT 0 65535;
BA_DEF_ BO_  "GenMsgILSupport" ENUM  "No","Yes";
BA_DEF_ BO_  "GenMsgSendType" ENUM  "Cyclic","Event","NotUsed","NotUsed","NotUsed","Cyclic","NotUsed","IfActive","NoMsgSendType","NotUsed";
BA_DEF_ BU_  "ILUsed" ENUM  "No","Yes";
BA_DEF_ BU_  "NodeLayerModules" STRING ;
BA_DEF_DEF_  "BusType" "";
BA_DEF_DEF_  "GenSigSendType" "Cyclic";
BA_DEF_DEF_  "GenSigCycleTime" 0;
BA_DEF_DEF_  "GenSigInvalidValue" "/";
BA_DEF_DEF_  "GenSigStartValue" 0;
BA_DEF_DEF_  "VFrameFormat" "StandardCAN";
BA_DEF_DEF_  "CANFD_BRS" "1";
BA_DEF_DEF_  "GenMsgCycleTime" 0;
BA_DEF_DEF_  "GenMsgILSupport" "Yes";
BA_DEF_DEF_  "GenMsgSendType" "NoMsgSendType";
BA_DEF_DEF_  "ILUsed" "Yes";
BA_DEF_DEF_  "NodeLayerModules" "OSEKNM01.dll,CANoeILNLVector.dll";
BA_ "BusType" "CAN";
BA_ "GenMsgSendType" BO_ 459 0;
BA_ "GenMsgCycleTime" BO_ 459 10;
BA_ "VFrameFormat" BO_ 459 14;
BA_ "GenMsgSendType" BO_ 382 0;
BA_ "GenMsgCycleTime" BO_ 382 10;
BA_ "VFrameFormat" BO_ 382 14;
BA_ "GenMsgSendType" BO_ 384 0;
BA_ "GenMsgCycleTime" BO_ 384 10;
BA_ "VFrameFormat" BO_ 384 14;
BA_ "GenMsgSendType" BO_ 391 0;
BA_ "GenMsgCycleTime" BO_ 391 10;
BA_ "VFrameFormat" BO_ 391 14;
BA_ "GenMsgSendType" BO_ 404 0;
BA_ "GenMsgCycleTime" BO_ 404 10;
BA_ "VFrameFormat" BO_ 404 14;
BA_ "GenMsgSendType" BO_ 422 0;
BA_ "GenMsgCycleTime" BO_ 422 10;
BA_ "VFrameFormat" BO_ 422 14;
BA_ "GenMsgSendType" BO_ 424 0;
BA_ "GenMsgCycleTime" BO_ 424 10;
BA_ "VFrameFormat" BO_ 424 14;
BA_ "GenMsgSendType" BO_ 454 0;
BA_ "GenMsgCycleTime" BO_ 454 10;
BA_ "VFrameFormat" BO_ 454 14;
BA_ "GenMsgSendType" BO_ 518 0;
BA_ "GenMsgCycleTime" BO_ 518 20;
BA_ "VFrameFormat" BO_ 518 14;
BA_ "GenMsgSendType" BO_ 583 0;
BA_ "GenMsgCycleTime" BO_ 583 20;
BA_ "VFrameFormat" BO_ 583 14;
BA_ "GenMsgSendType" BO_ 591 0;
BA_ "GenMsgCycleTime" BO_ 591 20;
BA_ "VFrameFormat" BO_ 591 14;
BA_ "GenMsgSendType" BO_ 651 0;
BA_ "GenMsgCycleTime" BO_ 651 40;
BA_ "VFrameFormat" BO_ 651 14;
BA_ "GenMsgSendType" BO_ 652 0;
BA_ "GenMsgCycleTime" BO_ 652 40;
BA_ "VFrameFormat" BO_ 652 14;
BA_ "GenMsgSendType" BO_ 676 0;
BA_ "GenMsgCycleTime" BO_ 676 50;
BA_ "VFrameFormat" BO_ 676 14;
BA_ "GenMsgSendType" BO_ 832 0;
BA_ "GenMsgCycleTime" BO_ 832 100;
BA_ "VFrameFormat" BO_ 832 14;
BA_ "GenMsgSendType" BO_ 866 0;
BA_ "GenMsgCycleTime" BO_ 866 100;
BA_ "VFrameFormat" BO_ 866 14;
BA_ "GenMsgSendType" BO_ 870 0;
BA_ "GenMsgCycleTime" BO_ 870 100;
BA_ "VFrameFormat" BO_ 870 14;
BA_ "GenMsgSendType" BO_ 903 0;
BA_ "GenMsgCycleTime" BO_ 903 100;
BA_ "VFrameFormat" BO_ 903 14;
BA_ "GenMsgSendType" BO_ 912 0;
BA_ "GenMsgCycleTime" BO_ 912 500;
BA_ "VFrameFormat" BO_ 912 14;
BA_ "GenMsgSendType" BO_ 916 0;
BA_ "GenMsgCycleTime" BO_ 916 100;
BA_ "VFrameFormat" BO_ 916 14;
BA_ "GenMsgSendType" BO_ 922 0;
BA_ "GenMsgCycleTime" BO_ 922 100;
BA_ "VFrameFormat" BO_ 922 14;
BA_ "GenMsgSendType" BO_ 943 0;
BA_ "GenMsgCycleTime" BO_ 943 100;
BA_ "VFrameFormat" BO_ 943 14;
BA_ "GenMsgSendType" BO_ 952 0;
BA_ "GenMsgCycleTime" BO_ 952 100;
BA_ "VFrameFormat" BO_ 952 14;
BA_ "GenMsgSendType" BO_ 955 0;
BA_ "GenMsgCycleTime" BO_ 955 100;
BA_ "VFrameFormat" BO_ 955 14;
BA_ "GenMsgSendType" BO_ 962 0;
BA_ "GenMsgCycleTime" BO_ 962 100;
BA_ "VFrameFormat" BO_ 962 14;
BA_ "GenMsgSendType" BO_ 964 0;
BA_ "GenMsgCycleTime" BO_ 964 100;
BA_ "VFrameFormat" BO_ 964 14;
BA_ "GenMsgSendType" BO_ 966 0;
BA_ "GenMsgCycleTime" BO_ 966 100;
BA_ "VFrameFormat" BO_ 966 14;
BA_ "GenMsgSendType" BO_ 967 0;
BA_ "GenMsgCycleTime" BO_ 967 100;
BA_ "VFrameFormat" BO_ 967 14;
BA_ "GenMsgSendType" BO_ 999 0;
BA_ "GenMsgCycleTime" BO_ 999 100;
BA_ "VFrameFormat" BO_ 999 14;
BA_ "GenMsgSendType" BO_ 1000 0;
BA_ "GenMsgCycleTime" BO_ 1000 100;
BA_ "VFrameFormat" BO_ 1000 14;
BA_ "GenMsgSendType" BO_ 1023 0;
BA_ "GenMsgCycleTime" BO_ 1023 100;
BA_ "VFrameFormat" BO_ 1023 14;
BA_ "GenMsgSendType" BO_ 80 0;
BA_ "GenMsgCycleTime" BO_ 80 500;
BA_ "VFrameFormat" BO_ 80 14;
BA_ "GenMsgSendType" BO_ 1280 0;
BA_ "GenMsgCycleTime" BO_ 1280 1000;
BA_ "VFrameFormat" BO_ 1280 14;
BA_ "GenMsgSendType" BO_ 1281 0;
BA_ "GenMsgCycleTime" BO_ 1281 1000;
BA_ "VFrameFormat" BO_ 1281 14;
BA_ "GenMsgSendType" BO_ 1300 1;
BA_ "VFrameFormat" BO_ 1300 14;
BA_ "GenMsgSendType" BO_ 1328 0;
BA_ "GenMsgCycleTime" BO_ 1328 500;
BA_ "VFrameFormat" BO_ 1328 14;
BA_ "GenMsgSendType" BO_ 1684 0;
BA_ "GenMsgCycleTime" BO_ 1684 500;
BA_ "VFrameFormat" BO_ 1684 14;
BA_ "GenMsgSendType" BO_ 1882 1;
BA_ "VFrameFormat" BO_ 1882 14;
BA_ "GenMsgSendType" BO_ 1899 1;
BA_ "VFrameFormat" BO_ 1899 14;
BA_ "GenSigCycleTime" SG_ 459 IBCU_RollingCounter_1CB 10;
BA_ "GenSigCycleTime" SG_ 459 IBCU_CRCCheck_1CB 10;
BA_ "GenSigCycleTime" SG_ 459 IBCU_CRCCheck_237 10;
BA_ "GenSigCycleTime" SG_ 459 IBCU_RollingCounter_237 10;
BA_ "GenSigCycleTime" SG_ 459 IBCU_BrakePedalApplied 10;
BA_ "GenSigCycleTime" SG_ 382 EPS_RollingCounter_17E 10;
BA_ "GenSigInvalidValue" SG_ 382 EPS_MeasuredTorsionBarTorqValid "1";
BA_ "GenSigCycleTime" SG_ 382 EPS_MeasuredTorsionBarTorqValid 10;
BA_ "GenSigStartValue" SG_ 382 EPS_MeasuredTorsionBarTorque 1023;
BA_ "GenSigInvalidValue" SG_ 382 EPS_MeasuredTorsionBarTorque "2047";
BA_ "GenSigCycleTime" SG_ 382 EPS_MeasuredTorsionBarTorque 10;
BA_ "GenSigInvalidValue" SG_ 382 EPS_LatCtrlAvailabilityStatus "2";
BA_ "GenSigCycleTime" SG_ 382 EPS_LatCtrlAvailabilityStatus 10;
BA_ "GenSigInvalidValue" SG_ 382 EPS_LatCtrlActive "0";
BA_ "GenSigCycleTime" SG_ 382 EPS_LatCtrlActive 10;
BA_ "GenSigCycleTime" SG_ 382 EPS_CRCCheck_17E 10;
BA_ "GenSigCycleTime" SG_ 384 SAS_TrimmingSts 10;
BA_ "GenSigInvalidValue" SG_ 384 SAS_SteeringAngleValid "1";
BA_ "GenSigCycleTime" SG_ 384 SAS_SteeringAngleValid 10;
BA_ "GenSigInvalidValue" SG_ 384 SAS_SteeringAngleSpeed "255";
BA_ "GenSigCycleTime" SG_ 384 SAS_SteeringAngleSpeed 10;
BA_ "GenSigInvalidValue" SG_ 384 SAS_SteeringAngle "32767";
BA_ "GenSigCycleTime" SG_ 384 SAS_SteeringAngle 10;
BA_ "GenSigInvalidValue" SG_ 384 SAS_SASFailure "1";
BA_ "GenSigCycleTime" SG_ 384 SAS_SASFailure 10;
BA_ "GenSigCycleTime" SG_ 384 SAS_RollingCounter 10;
BA_ "GenSigCycleTime" SG_ 384 SAS_CRCCheck 10;
BA_ "GenSigCycleTime" SG_ 384 SAS_Calibrated 10;
BA_ "GenSigInvalidValue" SG_ 391 ESP_VehicleSpeedValid "1";
BA_ "GenSigCycleTime" SG_ 391 ESP_VehicleSpeedValid 10;
BA_ "GenSigInvalidValue" SG_ 391 ESP_VehicleSpeed "8191";
BA_ "GenSigCycleTime" SG_ 391 ESP_VehicleSpeed 10;
BA_ "GenSigCycleTime" SG_ 391 ESP_TCSFailStatus 10;
BA_ "GenSigCycleTime" SG_ 391 ESP_RollingCounter_187 10;
BA_ "GenSigStartValue" SG_ 391 ESP_ESPFunctionStatus 1;
BA_ "GenSigCycleTime" SG_ 391 ESP_ESPFunctionStatus 10;
BA_ "GenSigCycleTime" SG_ 391 ESP_ESPActiveStatus 10;
BA_ "GenSigCycleTime" SG_ 391 ESP_CRCCheck_187 10;
BA_ "GenSigCycleTime" SG_ 391 ESP_ABSFailStatus 10;
BA_ "GenSigCycleTime" SG_ 404 EMS_RollingCounter_194 10;
BA_ "GenSigCycleTime" SG_ 404 EMS_EngSts 10;
BA_ "GenSigInvalidValue" SG_ 404 EMS_EngSpd "65535";
BA_ "GenSigCycleTime" SG_ 404 EMS_EngSpd 10;
BA_ "GenSigCycleTime" SG_ 404 EMS_CRCCheck_194 10;
BA_ "GenSigCycleTime" SG_ 422 PCU_PwrTrainSts 10;
BA_ "GenSigCycleTime" SG_ 422 PCU_AccPedl 10;
BA_ "GenSigInvalidValue" SG_ 424 TCU_ShiftPostionValid "1";
BA_ "GenSigCycleTime" SG_ 424 TCU_ShiftPostionValid 10;
BA_ "GenSigCycleTime" SG_ 424 TCU_ShiftInProgressVld 10;
BA_ "GenSigCycleTime" SG_ 424 TCU_ShiftInProgress 10;
BA_ "GenSigCycleTime" SG_ 424 TCU_RollingCounter_1A8 10;
BA_ "GenSigStartValue" SG_ 424 TCU_GearShiftPosition 13;
BA_ "GenSigInvalidValue" SG_ 424 TCU_GearShiftPosition "15";
BA_ "GenSigCycleTime" SG_ 424 TCU_GearShiftPosition 10;
BA_ "GenSigCycleTime" SG_ 424 TCU_CRCCheck_1A8 10;
BA_ "GenSigInvalidValue" SG_ 424 TCU_ActualDrivingGearValid "1";
BA_ "GenSigCycleTime" SG_ 424 TCU_ActualDrivingGearValid 10;
BA_ "GenSigInvalidValue" SG_ 424 TCU_ActualDrivingGear "15";
BA_ "GenSigCycleTime" SG_ 424 TCU_ActualDrivingGear 10;
BA_ "GenSigCycleTime" SG_ 454 PCU_TarGearReqValid 10;
BA_ "GenSigCycleTime" SG_ 454 PCU_TarGearReq 10;
BA_ "GenSigCycleTime" SG_ 454 PCU_RealAccPedlVld 10;
BA_ "GenSigCycleTime" SG_ 454 PCU_RealAccPedl 10;
BA_ "GenSigCycleTime" SG_ 518 ESP_CRCCheck_277 20;
BA_ "GenSigCycleTime" SG_ 518 ESP_RollingCounter_277 20;
BA_ "GenSigInvalidValue" SG_ 518 Wheel_Speed_RR_Valid_Data "1";
BA_ "GenSigCycleTime" SG_ 518 Wheel_Speed_RR_Valid_Data 20;
BA_ "GenSigInvalidValue" SG_ 518 Wheel_Speed_RR_Pulse "255";
BA_ "GenSigCycleTime" SG_ 518 Wheel_Speed_RR_Pulse 20;
BA_ "GenSigCycleTime" SG_ 518 Wheel_Speed_RR_Direction 20;
BA_ "GenSigInvalidValue" SG_ 518 Wheel_Speed_RR_Data "8191";
BA_ "GenSigCycleTime" SG_ 518 Wheel_Speed_RR_Data 20;
BA_ "GenSigInvalidValue" SG_ 518 Wheel_Speed_RL_Valid_Data "1";
BA_ "GenSigCycleTime" SG_ 518 Wheel_Speed_RL_Valid_Data 20;
BA_ "GenSigInvalidValue" SG_ 518 Wheel_Speed_RL_Pulse "255";
BA_ "GenSigCycleTime" SG_ 518 Wheel_Speed_RL_Pulse 20;
BA_ "GenSigInvalidValue" SG_ 518 Wheel_Speed_RL_Direction "3";
BA_ "GenSigCycleTime" SG_ 518 Wheel_Speed_RL_Direction 20;
BA_ "GenSigInvalidValue" SG_ 518 Wheel_Speed_RL_Data "8191";
BA_ "GenSigCycleTime" SG_ 518 Wheel_Speed_RL_Data 20;
BA_ "GenSigInvalidValue" SG_ 518 Wheel_Speed_FR_Valid_Data "1";
BA_ "GenSigCycleTime" SG_ 518 Wheel_Speed_FR_Valid_Data 20;
BA_ "GenSigInvalidValue" SG_ 518 Wheel_Speed_FR_Pulse "255";
BA_ "GenSigCycleTime" SG_ 518 Wheel_Speed_FR_Pulse 20;
BA_ "GenSigInvalidValue" SG_ 518 Wheel_Speed_FR_Direction "3";
BA_ "GenSigCycleTime" SG_ 518 Wheel_Speed_FR_Direction 20;
BA_ "GenSigInvalidValue" SG_ 518 Wheel_Speed_FR_Data "8191";
BA_ "GenSigCycleTime" SG_ 518 Wheel_Speed_FR_Data 20;
BA_ "GenSigInvalidValue" SG_ 518 Wheel_Speed_FL_Valid_Data "1";
BA_ "GenSigCycleTime" SG_ 518 Wheel_Speed_FL_Valid_Data 20;
BA_ "GenSigInvalidValue" SG_ 518 Wheel_Speed_FL_Pulse "255";
BA_ "GenSigCycleTime" SG_ 518 Wheel_Speed_FL_Pulse 20;
BA_ "GenSigInvalidValue" SG_ 518 Wheel_Speed_FL_Direction "3";
BA_ "GenSigCycleTime" SG_ 518 Wheel_Speed_FL_Direction 20;
BA_ "GenSigInvalidValue" SG_ 518 Wheel_Speed_FL_Data "8191";
BA_ "GenSigCycleTime" SG_ 518 Wheel_Speed_FL_Data 20;
BA_ "GenSigCycleTime" SG_ 518 ESP_YawRateValid 20;
BA_ "GenSigInvalidValue" SG_ 518 ESP_YawRate "16383";
BA_ "GenSigCycleTime" SG_ 518 ESP_YawRate 20;
BA_ "GenSigCycleTime" SG_ 518 ESP_VehicleStandstill 20;
BA_ "GenSigInvalidValue" SG_ 518 ESP_VDCActive "0";
BA_ "GenSigCycleTime" SG_ 518 ESP_VDCActive 20;
BA_ "GenSigInvalidValue" SG_ 518 ESP_TCSActive "0";
BA_ "GenSigCycleTime" SG_ 518 ESP_TCSActive 20;
BA_ "GenSigCycleTime" SG_ 518 ESP_RollingCounter_278 20;
BA_ "GenSigCycleTime" SG_ 518 ESP_RollingCounter_258 20;
BA_ "GenSigCycleTime" SG_ 518 ESP_RollingCounter_208 20;
BA_ "GenSigCycleTime" SG_ 518 ESP_RollingCounter_206 20;
BA_ "GenSigCycleTime" SG_ 518 ESP_PrefillAvailable 20;
BA_ "GenSigCycleTime" SG_ 518 ESP_PrefillActive 20;
BA_ "GenSigInvalidValue" SG_ 518 ESP_OnlyABSActive "0";
BA_ "GenSigCycleTime" SG_ 518 ESP_OnlyABSActive 20;
BA_ "GenSigCycleTime" SG_ 518 ESP_MasCylBrakePressureValid 20;
BA_ "GenSigInvalidValue" SG_ 518 ESP_MasCylBrakePressure "4095";
BA_ "GenSigCycleTime" SG_ 518 ESP_MasCylBrakePressure 20;
BA_ "GenSigInvalidValue" SG_ 518 ESP_LongAccel "1023";
BA_ "GenSigCycleTime" SG_ 518 ESP_LongAccel 20;
BA_ "GenSigInvalidValue" SG_ 518 ESP_LatAccel "255";
BA_ "GenSigCycleTime" SG_ 518 ESP_LatAccel 20;
BA_ "GenSigInvalidValue" SG_ 518 ESP_HDC_STATUS "3";
BA_ "GenSigCycleTime" SG_ 518 ESP_HDC_STATUS 20;
BA_ "GenSigCycleTime" SG_ 518 ESP_CRCCheck_278 20;
BA_ "GenSigCycleTime" SG_ 518 ESP_CRCCheck_258 20;
BA_ "GenSigCycleTime" SG_ 518 ESP_CRCCheck_208 20;
BA_ "GenSigCycleTime" SG_ 518 ESP_CRCCheck_206 20;
BA_ "GenSigCycleTime" SG_ 518 ESP_BrakeForce 20;
BA_ "GenSigCycleTime" SG_ 518 ESP_AWBavailable 20;
BA_ "GenSigCycleTime" SG_ 518 ESP_AWBactive 20;
BA_ "GenSigCycleTime" SG_ 518 ESP_AEBdecActive 20;
BA_ "GenSigCycleTime" SG_ 518 ESP_AEBAvailable 20;
BA_ "GenSigCycleTime" SG_ 518 ESP_ABAavailable 20;
BA_ "GenSigCycleTime" SG_ 518 ESP_ABAactive 20;
BA_ "GenSigCycleTime" SG_ 583 APA_APAOnOff 20;
BA_ "GenSigStartValue" SG_ 591 EPS_TorqueAssistMode 3;
BA_ "GenSigCycleTime" SG_ 591 EPS_TorqueAssistMode 20;
BA_ "GenSigCycleTime" SG_ 591 EPS_RollingCounter_24F 20;
BA_ "GenSigCycleTime" SG_ 591 EPS_IACC_abortreason 20;
BA_ "GenSigCycleTime" SG_ 591 EPS_CRCCheck_24F 20;
BA_ "GenSigInvalidValue" SG_ 591 EPS_ConcussAvailabilityStatus "2";
BA_ "GenSigCycleTime" SG_ 591 EPS_ConcussAvailabilityStatus 20;
BA_ "GenSigInvalidValue" SG_ 651 LCM_LASSwitch "3";
BA_ "GenSigCycleTime" SG_ 651 LCM_LASSwitch 40;
BA_ "GenSigInvalidValue" SG_ 651 BCM_TurnLightSwitchSts "3";
BA_ "GenSigCycleTime" SG_ 651 BCM_TurnLightSwitchSts 40;
BA_ "GenSigInvalidValue" SG_ 651 BCM_TurnIndicatorRight "3";
BA_ "GenSigCycleTime" SG_ 651 BCM_TurnIndicatorRight 40;
BA_ "GenSigInvalidValue" SG_ 651 BCM_TurnIndicatorLeft "3";
BA_ "GenSigCycleTime" SG_ 651 BCM_TurnIndicatorLeft 40;
BA_ "GenSigInvalidValue" SG_ 651 BCM_LowBeamStatus "3";
BA_ "GenSigCycleTime" SG_ 651 BCM_LowBeamStatus 40;
BA_ "GenSigCycleTime" SG_ 651 BCM_HoodStatus 40;
BA_ "GenSigInvalidValue" SG_ 651 BCM_HighBeamStatus "3";
BA_ "GenSigCycleTime" SG_ 651 BCM_HighBeamStatus 40;
BA_ "GenSigInvalidValue" SG_ 651 BCM_emergencylightstatus "3";
BA_ "GenSigCycleTime" SG_ 651 BCM_emergencylightstatus 40;
BA_ "GenSigCycleTime" SG_ 651 BCM_DriverDoorStatus 40;
BA_ "GenSigCycleTime" SG_ 652 GW_MFS_RollingCounter_28C 40;
BA_ "GenSigInvalidValue" SG_ 652 GW_MFS_IACCenable_switch_signal "3";
BA_ "GenSigCycleTime" SG_ 652 GW_MFS_IACCenable_switch_signal 40;
BA_ "GenSigCycleTime" SG_ 652 GW_MFS_CRCCheck_28C 40;
BA_ "GenSigCycleTime" SG_ 676 LCDAR_RollingCounter_2AF 50;
BA_ "GenSigCycleTime" SG_ 676 LCDAR_Left_ELK_oAlert 50;
BA_ "GenSigInvalidValue" SG_ 676 LCDAR_ELK_oStatus "3";
BA_ "GenSigCycleTime" SG_ 676 LCDAR_ELK_oStatus 50;
BA_ "GenSigCycleTime" SG_ 676 LCDAR_ELK_oAlert 50;
BA_ "GenSigCycleTime" SG_ 676 LCDAR_CRCCheck_2AF 50;
BA_ "GenSigInvalidValue" SG_ 832 AC_FrBlowType "7";
BA_ "GenSigCycleTime" SG_ 832 AC_FrBlowType 100;
BA_ "GenSigCycleTime" SG_ 866 PCU_DrvMod 100;
BA_ "GenSigInvalidValue" SG_ 870 AC_EnvironmentalTempVD "1";
BA_ "GenSigCycleTime" SG_ 870 AC_EnvironmentalTempVD 100;
BA_ "GenSigStartValue" SG_ 870 AC_EnvironmentalTemp 255;
BA_ "GenSigInvalidValue" SG_ 870 AC_EnvironmentalTemp "255";
BA_ "GenSigCycleTime" SG_ 870 AC_EnvironmentalTemp 100;
BA_ "GenSigStartValue" SG_ 903 BCM_RainfallLevel 14;
BA_ "GenSigInvalidValue" SG_ 903 BCM_RainfallLevel "15";
BA_ "GenSigCycleTime" SG_ 903 BCM_RainfallLevel 100;
BA_ "GenSigInvalidValue" SG_ 903 BCM_FrontWiperStatus "3";
BA_ "GenSigCycleTime" SG_ 903 BCM_FrontWiperStatus 100;
BA_ "GenSigStartValue" SG_ 912 BCM_SOH_LifePercent 255;
BA_ "GenSigInvalidValue" SG_ 912 BCM_SOH_LifePercent "255";
BA_ "GenSigCycleTime" SG_ 912 BCM_SOH_LifePercent 500;
BA_ "GenSigCycleTime" SG_ 912 BCM_PMSLevel 500;
BA_ "GenSigInvalidValue" SG_ 916 HU_TLAEnable "0";
BA_ "GenSigCycleTime" SG_ 916 HU_TLAEnable 100;
BA_ "GenSigInvalidValue" SG_ 916 HU_ELKEnable "0";
BA_ "GenSigCycleTime" SG_ 916 HU_ELKEnable 100;
BA_ "GenSigCycleTime" SG_ 922 LAS_TSRWarningSign 100;
BA_ "GenSigInvalidValue" SG_ 922 LAS_TSRStatus "7";
BA_ "GenSigCycleTime" SG_ 922 LAS_TSRStatus 100;
BA_ "GenSigInvalidValue" SG_ 922 LAS_TSRRightLaneStatus "7";
BA_ "GenSigCycleTime" SG_ 922 LAS_TSRRightLaneStatus 100;
BA_ "GenSigInvalidValue" SG_ 922 LAS_TSRRightLaneSpdLimit "254";
BA_ "GenSigCycleTime" SG_ 922 LAS_TSRRightLaneSpdLimit 100;
BA_ "GenSigCycleTime" SG_ 922 LAS_TSRProhibitionSign 100;
BA_ "GenSigCycleTime" SG_ 922 LAS_TSRMandatorySign 100;
BA_ "GenSigInvalidValue" SG_ 922 LAS_TSRLeftLaneStatus "7";
BA_ "GenSigCycleTime" SG_ 922 LAS_TSRLeftLaneStatus 100;
BA_ "GenSigInvalidValue" SG_ 922 LAS_TSRLeftLaneSpdLimit "254";
BA_ "GenSigCycleTime" SG_ 922 LAS_TSRLeftLaneSpdLimit 100;
BA_ "GenSigInvalidValue" SG_ 922 LAS_TSRHostSpdLimitUnits "0";
BA_ "GenSigCycleTime" SG_ 922 LAS_TSRHostSpdLimitUnits 100;
BA_ "GenSigInvalidValue" SG_ 922 LAS_TSRHostSpdLimit "254";
BA_ "GenSigCycleTime" SG_ 922 LAS_TSRHostSpdLimit 100;
BA_ "GenSigCycleTime" SG_ 922 LAS_TSREnable 100;
BA_ "GenSigCycleTime" SG_ 922 LAS_TLAWarninglevel 100;
BA_ "GenSigStartValue" SG_ 922 LAS_TLAStopLine_HostLane 255;
BA_ "GenSigCycleTime" SG_ 922 LAS_TLAStopLine_HostLane 100;
BA_ "GenSigInvalidValue" SG_ 922 LAS_TLAStatus "3";
BA_ "GenSigCycleTime" SG_ 922 LAS_TLAStatus 100;
BA_ "GenSigCycleTime" SG_ 922 LAS_TLAObjectType_RightLane 100;
BA_ "GenSigCycleTime" SG_ 922 LAS_TLAObjectType_LeftLane 100;
BA_ "GenSigCycleTime" SG_ 922 LAS_TLAObjectType_HostLane 100;
BA_ "GenSigCycleTime" SG_ 922 LAS_TLAObjectStatus_RightLane 100;
BA_ "GenSigCycleTime" SG_ 922 LAS_TLAObjectStatus_LeftLane 100;
BA_ "GenSigCycleTime" SG_ 922 LAS_TLAObjectStatus_HostLane 100;
BA_ "GenSigCycleTime" SG_ 922 LAS_TLAObjectDetection_RightLane 100;
BA_ "GenSigCycleTime" SG_ 922 LAS_TLAObjectDetection_LeftLane 100;
BA_ "GenSigCycleTime" SG_ 922 LAS_TLAObjectDetection_HostLane 100;
BA_ "GenSigCycleTime" SG_ 922 LAS_TLAObjectColour_RightLane 100;
BA_ "GenSigCycleTime" SG_ 922 LAS_TLAObjectColour_LeftLane 100;
BA_ "GenSigCycleTime" SG_ 922 LAS_TLAObjectColour_HostLane 100;
BA_ "GenSigCycleTime" SG_ 922 LAS_TLAEnable 100;
BA_ "GenSigStartValue" SG_ 922 LAS_TLADistance_HostLane 255;
BA_ "GenSigCycleTime" SG_ 922 LAS_TLADistance_HostLane 100;
BA_ "GenSigCycleTime" SG_ 922 LAS_TLACountDownTime_HostLane 100;
BA_ "GenSigCycleTime" SG_ 922 LAS_TLAArrowDirection_RightLane 100;
BA_ "GenSigCycleTime" SG_ 922 LAS_TLAArrowDirection_LeftLane 100;
BA_ "GenSigCycleTime" SG_ 922 LAS_TLAArrowDirection_HostLane 100;
BA_ "GenSigCycleTime" SG_ 922 LAS_RollingCounter_3D4 100;
BA_ "GenSigCycleTime" SG_ 922 LAS_RollingCounter_3C0 100;
BA_ "GenSigCycleTime" SG_ 922 LAS_RollingCounter_37D 100;
BA_ "GenSigCycleTime" SG_ 922 LAS_RollingCounter_332 100;
BA_ "GenSigStartValue" SG_ 922 LAS_OverspeedWarningOffset 10;
BA_ "GenSigCycleTime" SG_ 922 LAS_OverspeedWarningOffset 100;
BA_ "GenSigCycleTime" SG_ 922 LAS_OverspeedWarningEnableStatus 100;
BA_ "GenSigCycleTime" SG_ 922 LAS_OverspeedVisualWarning 100;
BA_ "GenSigCycleTime" SG_ 922 LAS_OverspeedSoundWarningEnSt 100;
BA_ "GenSigCycleTime" SG_ 922 LAS_OverspeedSoundWarning 100;
BA_ "GenSigInvalidValue" SG_ 922 LAS_HMAStatus "3";
BA_ "GenSigCycleTime" SG_ 922 LAS_HMAStatus 100;
BA_ "GenSigCycleTime" SG_ 922 LAS_HMALightDistribution 100;
BA_ "GenSigCycleTime" SG_ 922 LAS_HMAEnableStatus 100;
BA_ "GenSigInvalidValue" SG_ 922 LAS_FrontCameraFailureStatus "3";
BA_ "GenSigCycleTime" SG_ 922 LAS_FrontCameraFailureStatus 100;
BA_ "GenSigInvalidValue" SG_ 922 LAS_FrontCameraCalibrationStatus "3";
BA_ "GenSigCycleTime" SG_ 922 LAS_FrontCameraCalibrationStatus 100;
BA_ "GenSigCycleTime" SG_ 922 LAS_CRCCheck_3D4 100;
BA_ "GenSigCycleTime" SG_ 922 LAS_CRCCheck_3C0 100;
BA_ "GenSigCycleTime" SG_ 922 LAS_CRCCheck_37D 100;
BA_ "GenSigCycleTime" SG_ 922 LAS_CRCCheck_332 100;
BA_ "GenSigCycleTime" SG_ 943 HU_RollingCounter_3AF 100;
BA_ "GenSigInvalidValue" SG_ 943 HU_RampInfo "0";
BA_ "GenSigCycleTime" SG_ 943 HU_RampInfo 100;
BA_ "GenSigStartValue" SG_ 943 HU_RampDistance 1023;
BA_ "GenSigInvalidValue" SG_ 943 HU_RampDistance "1023";
BA_ "GenSigCycleTime" SG_ 943 HU_RampDistance 100;
BA_ "GenSigInvalidValue" SG_ 943 HU_NavStatus "1";
BA_ "GenSigCycleTime" SG_ 943 HU_NavStatus 100;
BA_ "GenSigInvalidValue" SG_ 943 HU_NavSpeedLimitUnits "0";
BA_ "GenSigCycleTime" SG_ 943 HU_NavSpeedLimitUnits 100;
BA_ "GenSigInvalidValue" SG_ 943 HU_NavSpeedLimitType "0";
BA_ "GenSigCycleTime" SG_ 943 HU_NavSpeedLimitType 100;
BA_ "GenSigInvalidValue" SG_ 943 HU_NavSpeedLimitStatus "1";
BA_ "GenSigCycleTime" SG_ 943 HU_NavSpeedLimitStatus 100;
BA_ "GenSigStartValue" SG_ 943 HU_NavSpeedLimit 254;
BA_ "GenSigInvalidValue" SG_ 943 HU_NavSpeedLimit "255";
BA_ "GenSigCycleTime" SG_ 943 HU_NavSpeedLimit 100;
BA_ "GenSigInvalidValue" SG_ 943 HU_NavCurrentRoadType "0";
BA_ "GenSigCycleTime" SG_ 943 HU_NavCurrentRoadType 100;
BA_ "GenSigInvalidValue" SG_ 943 HU_NavCountryCode "0";
BA_ "GenSigCycleTime" SG_ 943 HU_NavCountryCode 100;
BA_ "GenSigInvalidValue" SG_ 943 HU_EnterRampInfo "0";
BA_ "GenSigCycleTime" SG_ 943 HU_EnterRampInfo 100;
BA_ "GenSigInvalidValue" SG_ 943 HU_EnterCurveInfo "0";
BA_ "GenSigCycleTime" SG_ 943 HU_EnterCurveInfo 100;
BA_ "GenSigStartValue" SG_ 943 HU_CurveDistance 63;
BA_ "GenSigInvalidValue" SG_ 943 HU_CurveDistance "63";
BA_ "GenSigCycleTime" SG_ 943 HU_CurveDistance 100;
BA_ "GenSigCycleTime" SG_ 943 HU_CRCCheck_3AF 100;
BA_ "GenSigStartValue" SG_ 952 HU_TunnelLength 63;
BA_ "GenSigInvalidValue" SG_ 952 HU_TunnelLength "63";
BA_ "GenSigCycleTime" SG_ 952 HU_TunnelLength 100;
BA_ "GenSigStartValue" SG_ 952 HU_TunnelDistance 63;
BA_ "GenSigInvalidValue" SG_ 952 HU_TunnelDistance "63";
BA_ "GenSigCycleTime" SG_ 952 HU_TunnelDistance 100;
BA_ "GenSigStartValue" SG_ 952 HU_SlopeDistance 63;
BA_ "GenSigInvalidValue" SG_ 952 HU_SlopeDistance "63";
BA_ "GenSigCycleTime" SG_ 952 HU_SlopeDistance 100;
BA_ "GenSigCycleTime" SG_ 952 HU_RollingCounter_3B8 100;
BA_ "GenSigStartValue" SG_ 952 HU_RoadCurvatureFar 511;
BA_ "GenSigInvalidValue" SG_ 952 HU_RoadCurvatureFar "1023";
BA_ "GenSigCycleTime" SG_ 952 HU_RoadCurvatureFar 100;
BA_ "GenSigStartValue" SG_ 952 HU_RoadCurvature 511;
BA_ "GenSigInvalidValue" SG_ 952 HU_RoadCurvature "1023";
BA_ "GenSigCycleTime" SG_ 952 HU_RoadCurvature 100;
BA_ "GenSigInvalidValue" SG_ 952 HU_NavGuiganceStatus "3";
BA_ "GenSigCycleTime" SG_ 952 HU_NavGuiganceStatus 100;
BA_ "GenSigInvalidValue" SG_ 952 HU_EnterTunnelInfo "0";
BA_ "GenSigCycleTime" SG_ 952 HU_EnterTunnelInfo 100;
BA_ "GenSigInvalidValue" SG_ 952 HU_EnterSlopeInfo "0";
BA_ "GenSigCycleTime" SG_ 952 HU_EnterSlopeInfo 100;
BA_ "GenSigCycleTime" SG_ 952 HU_CRCCheck_3B8 100;
BA_ "GenSigInvalidValue" SG_ 952 HU_Byroad "3";
BA_ "GenSigCycleTime" SG_ 952 HU_Byroad 100;
BA_ "GenSigStartValue" SG_ 955 HU_SpeedLimitDistance 63;
BA_ "GenSigInvalidValue" SG_ 955 HU_SpeedLimitDistance "63";
BA_ "GenSigCycleTime" SG_ 955 HU_SpeedLimitDistance 100;
BA_ "GenSigStartValue" SG_ 962 HU_TrafficAccident_Info 3;
BA_ "GenSigInvalidValue" SG_ 962 HU_TrafficAccident_Info "3";
BA_ "GenSigCycleTime" SG_ 962 HU_TrafficAccident_Info 100;
BA_ "GenSigStartValue" SG_ 962 HU_TollInfo 3;
BA_ "GenSigInvalidValue" SG_ 962 HU_TollInfo "3";
BA_ "GenSigCycleTime" SG_ 962 HU_TollInfo 100;
BA_ "GenSigStartValue" SG_ 962 HU_TollDis 63;
BA_ "GenSigInvalidValue" SG_ 962 HU_TollDis "63";
BA_ "GenSigCycleTime" SG_ 962 HU_TollDis 100;
BA_ "GenSigStartValue" SG_ 962 HU_To_TrafficAccident_Dis 63;
BA_ "GenSigInvalidValue" SG_ 962 HU_To_TrafficAccident_Dis "63";
BA_ "GenSigCycleTime" SG_ 962 HU_To_TrafficAccident_Dis 100;
BA_ "GenSigStartValue" SG_ 962 HU_To_Construction_Dis 63;
BA_ "GenSigInvalidValue" SG_ 962 HU_To_Construction_Dis "63";
BA_ "GenSigCycleTime" SG_ 962 HU_To_Construction_Dis 100;
BA_ "GenSigStartValue" SG_ 962 HU_To_Branch_Dis 63;
BA_ "GenSigInvalidValue" SG_ 962 HU_To_Branch_Dis "63";
BA_ "GenSigCycleTime" SG_ 962 HU_To_Branch_Dis 100;
BA_ "GenSigCycleTime" SG_ 962 HU_RollingCounter_3C2 100;
BA_ "GenSigInvalidValue" SG_ 962 HU_Road_TrafficFlow "7";
BA_ "GenSigCycleTime" SG_ 962 HU_Road_TrafficFlow 100;
BA_ "GenSigInvalidValue" SG_ 962 HU_RampSide "0";
BA_ "GenSigCycleTime" SG_ 962 HU_RampSide 100;
BA_ "GenSigInvalidValue" SG_ 962 HU_MapDataUpdateStatus "7";
BA_ "GenSigCycleTime" SG_ 962 HU_MapDataUpdateStatus 100;
BA_ "GenSigInvalidValue" SG_ 962 HU_LaneCnt "0";
BA_ "GenSigCycleTime" SG_ 962 HU_LaneCnt 100;
BA_ "GenSigInvalidValue" SG_ 962 HU_ForwardRoadType "0";
BA_ "GenSigCycleTime" SG_ 962 HU_ForwardRoadType 100;
BA_ "GenSigStartValue" SG_ 962 HU_FallingRockInfo 3;
BA_ "GenSigInvalidValue" SG_ 962 HU_FallingRockInfo "3";
BA_ "GenSigCycleTime" SG_ 962 HU_FallingRockInfo 100;
BA_ "GenSigStartValue" SG_ 962 HU_FallingRockDi 63;
BA_ "GenSigInvalidValue" SG_ 962 HU_FallingRockDi "63";
BA_ "GenSigCycleTime" SG_ 962 HU_FallingRockDi 100;
BA_ "GenSigCycleTime" SG_ 962 HU_CRCCheck_3C2 100;
BA_ "GenSigStartValue" SG_ 962 HU_Construction_Info 3;
BA_ "GenSigInvalidValue" SG_ 962 HU_Construction_Info "3";
BA_ "GenSigCycleTime" SG_ 962 HU_Construction_Info 100;
BA_ "GenSigStartValue" SG_ 964 HU_To_NumchangeOfLanes_Dist 63;
BA_ "GenSigInvalidValue" SG_ 964 HU_To_NumchangeOfLanes_Dist "63";
BA_ "GenSigCycleTime" SG_ 964 HU_To_NumchangeOfLanes_Dist 100;
BA_ "GenSigCycleTime" SG_ 964 HU_RollingCounter_3C4 100;
BA_ "GenSigStartValue" SG_ 964 HU_RoadCurvature_40m 511;
BA_ "GenSigInvalidValue" SG_ 964 HU_RoadCurvature_40m "1023";
BA_ "GenSigCycleTime" SG_ 964 HU_RoadCurvature_40m 100;
BA_ "GenSigStartValue" SG_ 964 HU_RoadCurvature_30m 511;
BA_ "GenSigInvalidValue" SG_ 964 HU_RoadCurvature_30m "1023";
BA_ "GenSigCycleTime" SG_ 964 HU_RoadCurvature_30m 100;
BA_ "GenSigStartValue" SG_ 964 HU_RoadCurvature_20m 511;
BA_ "GenSigInvalidValue" SG_ 964 HU_RoadCurvature_20m "1023";
BA_ "GenSigCycleTime" SG_ 964 HU_RoadCurvature_20m 100;
BA_ "GenSigStartValue" SG_ 964 HU_RoadCurvature_10m 511;
BA_ "GenSigInvalidValue" SG_ 964 HU_RoadCurvature_10m "1023";
BA_ "GenSigCycleTime" SG_ 964 HU_RoadCurvature_10m 100;
BA_ "GenSigStartValue" SG_ 964 HU_Lane_Changtype 3;
BA_ "GenSigInvalidValue" SG_ 964 HU_Lane_Changtype "3";
BA_ "GenSigCycleTime" SG_ 964 HU_Lane_Changtype 100;
BA_ "GenSigCycleTime" SG_ 964 HU_CRCCheck_3C4 100;
BA_ "GenSigCycleTime" SG_ 966 HU_RollingCounter_3C6 100;
BA_ "GenSigStartValue" SG_ 966 HU_RoadCurvature_90m 511;
BA_ "GenSigInvalidValue" SG_ 966 HU_RoadCurvature_90m "1023";
BA_ "GenSigCycleTime" SG_ 966 HU_RoadCurvature_90m 100;
BA_ "GenSigStartValue" SG_ 966 HU_RoadCurvature_80m 511;
BA_ "GenSigInvalidValue" SG_ 966 HU_RoadCurvature_80m "1023";
BA_ "GenSigCycleTime" SG_ 966 HU_RoadCurvature_80m 100;
BA_ "GenSigStartValue" SG_ 966 HU_RoadCurvature_70m 511;
BA_ "GenSigInvalidValue" SG_ 966 HU_RoadCurvature_70m "1023";
BA_ "GenSigCycleTime" SG_ 966 HU_RoadCurvature_70m 100;
BA_ "GenSigStartValue" SG_ 966 HU_RoadCurvature_60m 511;
BA_ "GenSigInvalidValue" SG_ 966 HU_RoadCurvature_60m "1023";
BA_ "GenSigCycleTime" SG_ 966 HU_RoadCurvature_60m 100;
BA_ "GenSigStartValue" SG_ 966 HU_RoadCurvature_50m 511;
BA_ "GenSigInvalidValue" SG_ 966 HU_RoadCurvature_50m "1023";
BA_ "GenSigCycleTime" SG_ 966 HU_RoadCurvature_50m 100;
BA_ "GenSigCycleTime" SG_ 966 HU_CRCCheck_3C6 100;
BA_ "GenSigInvalidValue" SG_ 966 HU_BranchInfo "0";
BA_ "GenSigCycleTime" SG_ 966 HU_BranchInfo 100;
BA_ "GenSigStartValue" SG_ 967 HU_SlopeGradient_300m 1023;
BA_ "GenSigInvalidValue" SG_ 967 HU_SlopeGradient_300m "1023";
BA_ "GenSigCycleTime" SG_ 967 HU_SlopeGradient_300m 100;
BA_ "GenSigCycleTime" SG_ 967 HU_RollingCounter_3C7 100;
BA_ "GenSigStartValue" SG_ 967 HU_RoadCurvature_600m 511;
BA_ "GenSigInvalidValue" SG_ 967 HU_RoadCurvature_600m "1023";
BA_ "GenSigCycleTime" SG_ 967 HU_RoadCurvature_600m 100;
BA_ "GenSigStartValue" SG_ 967 HU_RoadCurvature_400m 511;
BA_ "GenSigInvalidValue" SG_ 967 HU_RoadCurvature_400m "1023";
BA_ "GenSigCycleTime" SG_ 967 HU_RoadCurvature_400m 100;
BA_ "GenSigStartValue" SG_ 967 HU_RoadCurvature_300m 511;
BA_ "GenSigInvalidValue" SG_ 967 HU_RoadCurvature_300m "1023";
BA_ "GenSigCycleTime" SG_ 967 HU_RoadCurvature_300m 100;
BA_ "GenSigStartValue" SG_ 967 HU_RoadCurvature_100m 511;
BA_ "GenSigInvalidValue" SG_ 967 HU_RoadCurvature_100m "1023";
BA_ "GenSigCycleTime" SG_ 967 HU_RoadCurvature_100m 100;
BA_ "GenSigInvalidValue" SG_ 967 HU_MapMatchStatus "3";
BA_ "GenSigCycleTime" SG_ 967 HU_MapMatchStatus 100;
BA_ "GenSigCycleTime" SG_ 967 HU_CRCCheck_3C7 100;
BA_ "GenSigStartValue" SG_ 999 BCM_T_BATT 255;
BA_ "GenSigInvalidValue" SG_ 999 BCM_T_BATT "255";
BA_ "GenSigCycleTime" SG_ 999 BCM_T_BATT 100;
BA_ "GenSigInvalidValue" SG_ 999 BCM_Status_Temp "0";
BA_ "GenSigCycleTime" SG_ 999 BCM_Status_Temp 100;
BA_ "GenSigStartValue" SG_ 1000 BCM_SOF_Q_STATE 3;
BA_ "GenSigInvalidValue" SG_ 1000 BCM_SOF_Q_STATE "3";
BA_ "GenSigCycleTime" SG_ 1000 BCM_SOF_Q_STATE 100;
BA_ "GenSigStartValue" SG_ 1000 BCM_SOF_Q 255;
BA_ "GenSigInvalidValue" SG_ 1000 BCM_SOF_Q "255";
BA_ "GenSigCycleTime" SG_ 1000 BCM_SOF_Q 100;
BA_ "GenSigInvalidValue" SG_ 1023 BCM_RearFoglampStatus "3";
BA_ "GenSigCycleTime" SG_ 1023 BCM_RearFoglampStatus 100;
BA_ "GenSigInvalidValue" SG_ 1023 BCM_FrontFoglampStatus "3";
BA_ "GenSigCycleTime" SG_ 1023 BCM_FrontFoglampStatus 100;
BA_ "GenSigInvalidValue" SG_ 1023 BCM_AutoHeadlightSts "0";
BA_ "GenSigCycleTime" SG_ 1023 BCM_AutoHeadlightSts 100;
BA_ "GenSigCycleTime" SG_ 80 SRS_WarningLampStatus 500;
BA_ "GenSigCycleTime" SG_ 80 SRS_RollingCounter_id050 500;
BA_ "GenSigCycleTime" SG_ 80 SRS_PassengerBuckleSwitchStatus 500;
BA_ "GenSigCycleTime" SG_ 80 SRS_DriverBuckleSwitchStatus 500;
BA_ "GenSigCycleTime" SG_ 80 SRS_CrashOutputStatusCheckSum 500;
BA_ "GenSigCycleTime" SG_ 80 SRS_CrashOutputStatus 500;
BA_ "GenSigInvalidValue" SG_ 1280 HU_CurrentLocationValid "1";
BA_ "GenSigCycleTime" SG_ 1280 HU_CurrentLocationValid 1000;
BA_ "GenSigInvalidValue" SG_ 1280 HU_CurrentLocationLongitude "536870911";
BA_ "GenSigCycleTime" SG_ 1280 HU_CurrentLocationLongitude 1000;
BA_ "GenSigInvalidValue" SG_ 1280 HU_CurrentLocationLatitude "268435455";
BA_ "GenSigCycleTime" SG_ 1280 HU_CurrentLocationLatitude 1000;
BA_ "GenSigInvalidValue" SG_ 1281 HU_LocalTimeYear "0";
BA_ "GenSigCycleTime" SG_ 1281 HU_LocalTimeYear 1000;
BA_ "GenSigInvalidValue" SG_ 1281 HU_LocalTimeValid "1";
BA_ "GenSigCycleTime" SG_ 1281 HU_LocalTimeValid 1000;
BA_ "GenSigInvalidValue" SG_ 1281 HU_LocalTimeSecond "0";
BA_ "GenSigCycleTime" SG_ 1281 HU_LocalTimeSecond 1000;
BA_ "GenSigStartValue" SG_ 1281 HU_LocalTimeMonth 1;
BA_ "GenSigInvalidValue" SG_ 1281 HU_LocalTimeMonth "1";
BA_ "GenSigCycleTime" SG_ 1281 HU_LocalTimeMonth 1000;
BA_ "GenSigInvalidValue" SG_ 1281 HU_LocalTimeMinute "0";
BA_ "GenSigCycleTime" SG_ 1281 HU_LocalTimeMinute 1000;
BA_ "GenSigInvalidValue" SG_ 1281 HU_LocalTimeHour "0";
BA_ "GenSigCycleTime" SG_ 1281 HU_LocalTimeHour 1000;
BA_ "GenSigStartValue" SG_ 1281 HU_LocalTimeDate 1;
BA_ "GenSigInvalidValue" SG_ 1281 HU_LocalTimeDate "1";
BA_ "GenSigCycleTime" SG_ 1281 HU_LocalTimeDate 1000;
BA_ "GenSigInvalidValue" SG_ 1328 IP_TotalOdometer "16777215";
BA_ "GenSigCycleTime" SG_ 1328 IP_TotalOdometer 500;
BA_ "GenSigCycleTime" SG_ 1684 LAS_DTC2_Status 500;
BA_ "GenSigCycleTime" SG_ 1684 LAS_DTC2_MiddByte 500;
BA_ "GenSigCycleTime" SG_ 1684 LAS_DTC2_LowByte 500;
BA_ "GenSigCycleTime" SG_ 1684 LAS_DTC2_HighByte 500;
BA_ "GenSigCycleTime" SG_ 1684 LAS_DTC1_Status 500;
BA_ "GenSigCycleTime" SG_ 1684 LAS_DTC1_MiddByte 500;
BA_ "GenSigCycleTime" SG_ 1684 LAS_DTC1_LowByte 500;
BA_ "GenSigCycleTime" SG_ 1684 LAS_DTC1_HighByte 500;
VAL_ 459 IBCU_BrakePedalApplied 1 "Brake Applied" 0 "Brake Not Applied" ;
VAL_ 382 EPS_MeasuredTorsionBarTorqValid 0 "Available" 1 "unavailable" ;
VAL_ 382 EPS_MeasuredTorsionBarTorque 1023 "" ;
VAL_ 382 EPS_LatCtrlAvailabilityStatus 0 "Not Availability " 1 "Availability" 2 "failure" 3 "Reserved" ;
VAL_ 382 EPS_LatCtrlActive 0 "Not Actived" 1 "Actived" ;
VAL_ 384 SAS_TrimmingSts 0 "Sensor Not trimmed£¬ this is handled as a sensor failure" 1 "Sensor trimmed" ;
VAL_ 384 SAS_SteeringAngleValid 0 "Valid " 1 "Invalid" ;
VAL_ 384 SAS_SASFailure 0 "No Failure" 1 "Failure" ;
VAL_ 384 SAS_Calibrated 0 "Calibrated" 1 "Not Calibrated" ;
VAL_ 391 ESP_VehicleSpeedValid 0 "Valid" 1 "NotValid" ;
VAL_ 391 ESP_VehicleSpeed 0 "0~360km/h" 6401 "Reserved" 8191 "Invalid" ;
VAL_ 391 ESP_TCSFailStatus 0 "No error" 1 "Error" ;
VAL_ 391 ESP_ESPFunctionStatus 0 "OFF" 1 "ON" ;
VAL_ 391 ESP_ESPActiveStatus 0 "NotActive" 1 "Active" ;
VAL_ 391 ESP_ABSFailStatus 0 "No error" 1 "Error" ;
VAL_ 404 EMS_EngSts 3 "Reserved" 2 "Running" 1 "Crank" 0 "Stop" ;
VAL_ 422 PCU_PwrTrainSts 3 "Reserved" 2 "Running" 1 "Crank" 0 "Stop" ;
VAL_ 424 TCU_ShiftPostionValid 0 "valid" 1 "Invalid" ;
VAL_ 424 TCU_ShiftInProgressVld 0 "Invalid" 1 "Valid" ;
VAL_ 424 TCU_ShiftInProgress 0 "Not shifting" 1 "Shifting" ;
VAL_ 424 TCU_GearShiftPosition 0 "Parking" 1 "Reverse" 2 "Neutral" 3 "D" 4 "D3" 5 "D2" 6 "L" 7 "M/S" 8 "Reserved" 13 "Initial value" 14 "Unreliable" 15 "Invalid" ;
VAL_ 424 TCU_ActualDrivingGearValid 0 "valid" 1 "Invalid" ;
VAL_ 424 TCU_ActualDrivingGear 0 "Neutral" 1 "1st gear" 2 "2nd gear" 3 "3rd gear" 4 "4th gear" 5 "5th gear" 6 "6th gear" 7 "7th gear" 8 "8th gear" 9 "Reverse" 10 "Parking" 11 "Reserved" 13 "Reserved" 14 "Reserved" 15 "Invalid" ;
VAL_ 454 PCU_TarGearReqValid 0 "Valid" 1 "Invalid" ;
VAL_ 454 PCU_TarGearReq 0 "Initial value" 1 "1st gear" 2 "2nd gear" 3 "3rd gear" 4 "4th gear" 5 "5th gear" 6 "6th gear" 7 "7th gear" 8 "8th gear" 9 "Reverse" 10 "Neutral" 11 "Reserved" 12 "Reserved" 14 "Reserved" 15 "Invalid" ;
VAL_ 454 PCU_RealAccPedlVld 1 "Invalid" 0 "valid" ;
VAL_ 518 Wheel_Speed_RR_Valid_Data 0 "Valid" 1 "NotValid" ;
VAL_ 518 Wheel_Speed_RR_Direction 0 "Forward" 1 "backward" 2 "Standstill" 3 "Invalid" ;
VAL_ 518 Wheel_Speed_RL_Valid_Data 0 "Valid" 1 "NotValid" ;
VAL_ 518 Wheel_Speed_RL_Direction 0 "Forward" 1 "backward" 2 "Standstill" 3 "Invalid" ;
VAL_ 518 Wheel_Speed_FR_Valid_Data 0 "Valid" 1 "NotValid" ;
VAL_ 518 Wheel_Speed_FR_Direction 0 "Forward" 1 "backward" 2 "Standstill" 3 "Invalid" ;
VAL_ 518 Wheel_Speed_FL_Valid_Data 0 "Valid" 1 "NotValid" ;
VAL_ 518 Wheel_Speed_FL_Direction 0 "Forward" 1 "backward" 2 "Standstill" 3 "Invalid" ;
VAL_ 518 ESP_YawRateValid 0 "Valid" 1 "Invalid" ;
VAL_ 518 ESP_VehicleStandstill 0 "Notstandstill" 1 "standstill" ;
VAL_ 518 ESP_VDCActive 0 "NotActive" 1 "Active" ;
VAL_ 518 ESP_TCSActive 0 "NotActive" 1 "Active" ;
VAL_ 518 ESP_PrefillAvailable 0 "Notavailable" 1 "available" ;
VAL_ 518 ESP_PrefillActive 0 "Notactive" 1 "Active" ;
VAL_ 518 ESP_OnlyABSActive 0 "NotActive" 1 "Active" ;
VAL_ 518 ESP_MasCylBrakePressureValid 0 "Valid" 1 "Invalid" ;
VAL_ 518 ESP_HDC_STATUS 0 "OFF" 1 "ON" 2 "Standby" 3 "Error" ;
VAL_ 518 ESP_BrakeForce 0 "Nobrakeforce" 1 "havebrakeforce" ;
VAL_ 518 ESP_AWBavailable 0 "Notavailable" 1 "available" ;
VAL_ 518 ESP_AWBactive 0 "Notactive" 1 "Active" ;
VAL_ 518 ESP_AEBdecActive 0 "Notactive" 1 "Active" ;
VAL_ 518 ESP_AEBAvailable 0 "Notavailable" 1 "available" ;
VAL_ 518 ESP_ABAavailable 0 "Notavailable" 1 "available" ;
VAL_ 518 ESP_ABAactive 0 "Notactive" 1 "Active" ;
VAL_ 583 APA_APAOnOff 0 "OFF" 1 "ON" ;
VAL_ 591 EPS_TorqueAssistMode 0 "Normal" 1 "light" 2 "heavy" 3 "unkNow" ;
VAL_ 591 EPS_IACC_abortreason 0 "No_DRIVING_INTERUPtion" 1 "DRIVER_RECOVERY(Over ride)" 2 "VEHICLE_SPEED ERROR" 3 "REQUEST ERROR" 4 "DAE_THERMAL_SECURITY" 5 "OTHER_DEFAULT" 6 "ADAS message Error(CD569:0x6=Reserved)" ;
VAL_ 591 EPS_ConcussAvailabilityStatus 0 "Concuss Availability" 1 "Concuss Active" 2 "EPS Concuss failure EPS" 3 "Reserved" ;
VAL_ 651 LCM_LASSwitch 0 "Not Push" 1 "Push" 2 "Reserved" 3 "Fault" ;
VAL_ 651 BCM_TurnLightSwitchSts 0 "Not Actived" 1 "Left Actived" 2 "Right Actived" 3 "Invalid" ;
VAL_ 651 BCM_TurnIndicatorRight 0 "OFF" 1 "ON" 2 "Not used" 3 "Error" ;
VAL_ 651 BCM_TurnIndicatorLeft 0 "OFF" 1 "ON" 2 "Not used" 3 "Error" ;
VAL_ 651 BCM_LowBeamStatus 0 "OFF" 1 "ON" 2 "Not used" 3 "Reserved" ;
VAL_ 651 BCM_HoodStatus 0 "Close" 1 "Open" ;
VAL_ 651 BCM_HighBeamStatus 0 "OFF" 1 "ON" 2 "Not used" 3 "Reserved" ;
VAL_ 651 BCM_emergencylightstatus 0 "OFF" 1 "ON" 2 "Not used" 3 "Error" ;
VAL_ 651 BCM_DriverDoorStatus 0 "Close" 1 "Open" ;
VAL_ 652 GW_MFS_IACCenable_switch_signal 0 "Button not pressed" 1 "Key press" 2 "Fake button" 3 "Error" ;
VAL_ 676 LCDAR_Left_ELK_oAlert 0 "No warning" 1 "level 1" 2 "level 2" 3 "Reserved" ;
VAL_ 676 LCDAR_ELK_oStatus 0 "OFF" 1 "Inactive" 2 "Active" 3 "Failure" ;
VAL_ 676 LCDAR_ELK_oAlert 0 "No warning" 1 "level 1" 2 "level 2" 3 "Reserved" ;
VAL_ 832 AC_FrBlowType 0 "blow face" 1 "blow face/blow feet" 2 "blow feet" 3 "blow fee/defroster" 4 "defroster" 5 "Reserved" 7 "Invalid" ;
VAL_ 866 PCU_DrvMod 0 "Reserved" 1 "iEV" 2 "iHEV" 3 "Reserved" 4 "eSPT" ;
VAL_ 870 AC_EnvironmentalTempVD 0 "Valid" 1 "Invalid" ;
VAL_ 870 AC_EnvironmentalTemp 0 "-40~87" 255 "Invalid" ;
VAL_ 903 BCM_RainfallLevel 0 "No rain" 1 "Level 1" 2 "Level 2" 3 "Level 3" 4 "Level 4" 5 "Level 5?" 6 "Level 6" 7 "Level 7" 8 "Level 8" 9 "Level 9" 10 "Level 10" 11 "Level 11" 12 "Level 12" 13 "level 13" 14 "init value" 15 "Invalid value" ;
VAL_ 903 BCM_FrontWiperStatus 0 "OFF" 1 "Low" 2 "High" 3 "Error" ;
VAL_ 912 BCM_SOH_LifePercent 0 "%0-100%" 101 "Reserved" 255 "Invalid" ;
VAL_ 912 BCM_PMSLevel 0 "Normal battery" 1 "Low battery" 2 "Too much power consumption" 3 "Reserved" ;
VAL_ 916 HU_TLAEnable 0 "Inactive " 1 "OFF" 2 "ON" 3 "Reserved" ;
VAL_ 916 HU_ELKEnable 0 "Inactive " 1 "OFF" 2 "ON" 3 "Reserved" ;
VAL_ 922 LAS_TSRWarningSign 0 "no display" 1 "Reverse detour" 2 "Continuous detour" 3 "Beware of pedestrians" 4 "Attention children" 5 "Slippery" 6 "tunnel" 7 "stroll" 8 "construction" 9 "reserved" ;
VAL_ 922 LAS_TSRStatus 0 "OFF" 1 "fusiON mode" 2 "visiON only mode" 3 "navigation only mode" 4 "Reserved" 5 "Reserved" 6 "Reserved" 7 "Invalid" ;
VAL_ 922 LAS_TSRRightLaneStatus 0 "OFF" 1 "fusiON mode" 2 "visiON only mode" 3 "navigation only mode" 4 "Reserved" 5 "Reserved" 6 "Reserved" 7 "Invalid" ;
VAL_ 922 LAS_TSRRightLaneSpdLimit 0 "No speed limit detected" 1 "SL5" 2 "SL10" 3 "SL15" 4 "SL20" 5 "SL25" 6 "SL30" 7 "SL35" 8 "SL40" 9 "SL45" 10 "SL50" 11 "SL55" 12 "SL60" 13 "SL65" 14 "SL70" 15 "SL75" 16 "SL80" 17 "SL85" 18 "SL90" 19 "SL95" 20 "SL100" 21 "SL105" 22 "SL110" 23 "SL115" 24 "SL120" 25 "SL125" 26 "SL130" 27 "SL135" 28 "SL140" 29 "SL145" 30 "SL150" 31 "SL155" 32 "SL160" 33 "Reserved" 254 "Unlimited" 255 "SLEND" ;
VAL_ 922 LAS_TSRProhibitionSign 0 "no display" 1 "No access" 2 "No entry" 3 "Prohibition of motor vehicles" 4 "No left turn" 5 "No right turn" 6 " No Straight" 7 "o U-turn" 8 "Overtaking is prohibited" 9 "Overtaking is prohibited" 10 "Temporary or long-term parking is prohibited" 11 "Long-term parking is prohibited Parking " 12 " No honking" 13 "Parking yield" 14 "Slow down yield" 15 "Traffic yield" 16 "reserved" ;
VAL_ 922 LAS_TSRMandatorySign 0 "no display" 1 "One way (straight)" 2 "walk" 3 "Trunk first" 4 "Car first" 5 "Crosswalk" 6 "Bus lane" 7 "reserved" ;
VAL_ 922 LAS_TSRLeftLaneStatus 0 "OFF" 1 "fusiON mode" 2 "visiON only mode" 3 "navigation only mode" 4 "Reserved" 5 "Reserved" 6 "Reserved" 7 "Invalid" ;
VAL_ 922 LAS_TSRLeftLaneSpdLimit 0 "No speed limit detected" 1 "SL5" 2 "SL10" 3 "SL15" 4 "SL20" 5 "SL25" 6 "SL30" 7 "SL35" 8 "SL40" 9 "SL45" 10 "SL50" 11 "SL55" 12 "SL60" 13 "SL65" 14 "SL70" 15 "SL75" 16 "SL80" 17 "SL85" 18 "SL90" 19 "SL95" 20 "SL100" 21 "SL105" 22 "SL110" 23 "SL115" 24 "SL120" 25 "SL125" 26 "SL130" 27 "SL135" 28 "SL140" 29 "SL145" 30 "SL150" 31 "SL155" 32 "SL160" 33 "Reserved" 254 "Unlimited" 255 "SLEND" ;
VAL_ 922 LAS_TSRHostSpdLimitUnits 0 "No display" 1 "unit kph" 2 "unit mph" 3 "Reserved" ;
VAL_ 922 LAS_TSRHostSpdLimit 0 "No speed limit detected" 1 "SL5" 2 "SL10" 3 "SL15" 4 "SL20" 5 "SL25" 6 "SL30" 7 "SL35" 8 "SL40" 9 "SL45" 10 "SL50" 11 "SL55" 12 "SL60" 13 "SL65" 14 "SL70" 15 "SL75" 16 "SL80" 17 "SL85" 18 "SL90" 19 "SL95" 20 "SL100" 21 "SL105" 22 "SL110" 23 "SL115" 24 "SL120" 25 "SL125" 26 "SL130" 27 "SL135" 28 "SL140" 29 "SL145" 30 "SL150" 31 "SL155" 32 "SL160" 33 "Reserved" 254 "Unlimited" 255 "SLEND" ;
VAL_ 922 LAS_TSREnable 0 "OFF" 1 "ON" ;
VAL_ 922 LAS_TLAWarninglevel 0 "No warning" 1 "Warning level 1" 2 "warning level 2" 3 "warning level 3." ;
VAL_ 922 LAS_TLAStopLine_HostLane 0 "0-250m" 251 "Reserved" 255 "Out of Range" ;
VAL_ 922 LAS_TLAStatus 0 "OFF" 1 "Standby" 2 "Active" 3 "Failure" ;
VAL_ 922 LAS_TLAObjectType_RightLane 0 "No display" 1 "Round" 2 "Arrow" 3 "Turn Round" 4 "X-type" 5 "Arrow+Trun
0x6-0x7=Reserved" ;
VAL_ 922 LAS_TLAObjectType_LeftLane 0 "No display" 1 "Round" 2 "Arrow" 3 "Turn Round" 4 "X-type" 5 "Arrow+Trun
0x6-0x7=Reserved" ;
VAL_ 922 LAS_TLAObjectType_HostLane 0 "No display" 1 "Round" 2 "Arrow" 3 "Turn Round" 4 "X-type" 5 "Arrow+Trun" 6 "Reserved" ;
VAL_ 922 LAS_TLAObjectStatus_RightLane 0 "No display" 1 "Lighting" 2 "Flashing" 3 "Disappear" ;
VAL_ 922 LAS_TLAObjectStatus_LeftLane 0 "No display" 1 "Lighting" 2 "Flashing" 3 "Disappear" ;
VAL_ 922 LAS_TLAObjectStatus_HostLane 0 "No display" 1 "Lighting" 2 "Flashing" 3 "Disappear" ;
VAL_ 922 LAS_TLAObjectDetection_RightLane 0 "Not Detected" 1 "Detected" ;
VAL_ 922 LAS_TLAObjectDetection_LeftLane 0 "Not Detected" 1 "Detected" ;
VAL_ 922 LAS_TLAObjectDetection_HostLane 0 "Not Detected" 1 "Detected" ;
VAL_ 922 LAS_TLAObjectColour_RightLane 0 "No display" 1 "Red" 2 "Yellow" 3 "Green" ;
VAL_ 922 LAS_TLAObjectColour_LeftLane 0 "No display" 1 "Red" 2 "Yellow" 3 "Green" ;
VAL_ 922 LAS_TLAObjectColour_HostLane 0 "No display" 1 "Red" 2 "Yellow" 3 "Green" ;
VAL_ 922 LAS_TLAEnable 0 "OFF" 1 "ON" ;
VAL_ 922 LAS_TLADistance_HostLane 0 "0-250m" 251 "Reserved" 255 "Out of Range" ;
VAL_ 922 LAS_TLACountDownTime_HostLane 0 "No display" 1 "1-120s" 121 "Reserved" 127 "out of range" ;
VAL_ 922 LAS_TLAArrowDirection_RightLane 0 "No display" 1 "Forward" 2 "Left" 3 "Forward +Left" 4 "Right" 5 "Forward +Right" 6 "Right+Left" 7 "Left+ Forward +Right" ;
VAL_ 922 LAS_TLAArrowDirection_LeftLane 0 "No display" 1 "Forward" 2 "Left" 3 "Forward +Left" 4 "Right" 5 "Forward +Right" 6 "Right+Left" 7 "Left+ Forward +Right" ;
VAL_ 922 LAS_TLAArrowDirection_HostLane 0 "No display" 1 "Forward" 2 "Left" 3 "Forward +Left" 4 "Right" 5 "Forward +Right" 6 "Right+Left" 7 "Left+ Forward +Right" ;
VAL_ 922 LAS_OverspeedWarningOffset 0 "" 21 "Reserved" 31 "Invalid" ;
VAL_ 922 LAS_OverspeedWarningEnableStatus 0 "OFF" 1 "ON" ;
VAL_ 922 LAS_OverspeedVisualWarning 0 "No Warning" 1 "Warning" ;
VAL_ 922 LAS_OverspeedSoundWarningEnSt 0 "OFF" 1 "ON" ;
VAL_ 922 LAS_OverspeedSoundWarning 0 "No Warning" 1 "Warning" ;
VAL_ 922 LAS_HMAStatus 0 "OFF" 1 "Standby" 2 "Active" 3 "Failure" ;
VAL_ 922 LAS_HMALightDistribution 0 "High beam Not recommended" 1 "High beam recommended" ;
VAL_ 922 LAS_HMAEnableStatus 0 "OFF" 1 "ON" ;
VAL_ 922 LAS_FrontCameraFailureStatus 0 "No Error" 1 "camera blocked" 2 "temporary failure" 3 "permanent failure" ;
VAL_ 922 LAS_FrontCameraCalibrationStatus 0 "Calibration is ok" 1 "Calibration In Process" 2 "Calibration never done" 3 "Calibration Failed" ;
VAL_ 943 HU_RampInfo 0 "Unknown" 1 "There is a ramp, but the car does not leave the high speed" 2 "The car enters the high speed through the ramp" 3 "The car exits the highway through the ramp" ;
VAL_ 943 HU_RampDistance 0 "0~3000m" 301 "Reserved" 1022 "Out of Range" 1023 "Unknown" ;
VAL_ 943 HU_NavStatus 0 "Normal" 1 "Error" ;
VAL_ 943 HU_NavSpeedLimitUnits 3 "Reserved" 2 "unit mph" 1 "unit kph" 0 "Unknown." ;
VAL_ 943 HU_NavSpeedLimitType 0 "Unknown" 1 "Speed-Limit Sign" 2 "Road Camera" 3 "Interval Velocity" ;
VAL_ 943 HU_NavSpeedLimitStatus 3 "Reserved" 2 "Reserved" 1 "Invalid" 0 "valid" ;
VAL_ 943 HU_NavSpeedLimit 0 "Unlimited" 1 "SL 5" 2 "SL 10" 32 "SL 160" 254 "Unknown" 255 "Invalid" ;
VAL_ 943 HU_NavCurrentRoadType 0 "Road Type Unknown£º Small road£¬ Walking Street" 1 "Road Type Class 1£º Secondary Roads" 2 "Road Type Class 2£º Mainly Road in City" 3 "Road Type Class 3£º Mainly Road in City£¬ Normal Province Road£¬ Mainly street" 4 "Road Type Class 4£º Province Road£¬ Mainly Road " 5 "Road Type Class 5£º Highway£¬ National Road£¬ Speed road" 6 "Reserved" 7 "Reserved" ;
VAL_ 943 HU_EnterRampInfo 0 "Unknown" 1 "Ramp entrance" 2 "On the ramp" 3 "Ramp exit" ;
VAL_ 943 HU_EnterCurveInfo 0 " unknown" 1 "Curved entrance" 2 "In a curve" 3 "Corner exit" ;
VAL_ 943 HU_CurveDistance 0 "0~600m" 61 "Out of Range" 62 "Reserved" 63 "Unknown" ;
VAL_ 952 HU_TunnelLength 0 "0~600m" 61 "Out of Range" 62 "Reserved" 63 "Unknown" ;
VAL_ 952 HU_TunnelDistance 0 "0~600m" 61 "Out of Range" 62 "Reserved" 63 "Unknown" ;
VAL_ 952 HU_SlopeDistance 0 "0~600m" 61 "Out of Range" 62 "Reserved" 63 "Unknown" ;
VAL_ 952 HU_RoadCurvatureFar 0 " -0.16192 ~ -0.00001, negative number represents curve to left" 8191 " 0,0 represents straight" 512 " 0.00001 ~ 0.16192,positive number represents curve to right" 1023 " unknown" ;
VAL_ 952 HU_RoadCurvature 0 " -0.16192 ~ -0.00001, negative number represents curve to left" 8191 " 0,0 represents straight" 512 " 0.00001 ~ 0.16192,positive number represents curve to right" 1023 " unknown" ;
VAL_ 952 HU_NavGuiganceStatus 0 "No navigation guidance path" 1 "With navigation guide path" 2 "Reserved" 3 "Reserved" ;
VAL_ 952 HU_EnterTunnelInfo 0 " unknown" 1 "Tunnel entrance" 2 "In the tunnel" 3 "Tunnel exit" ;
VAL_ 952 HU_EnterSlopeInfo 0 "unknown" 1 "Ramp entrance" 2 "In the ramp" 3 "Ramp exit" ;
VAL_ 952 HU_Byroad 0 "unknown" 1 "There is a byroad" 2 "No byroad" 3 "reserved" ;
VAL_ 955 HU_SpeedLimitDistance 0 "0~600m" 61 "Out of Range" 62 "Reserved" 63 "Unknown" ;
VAL_ 962 HU_TrafficAccident_Info 0 "No traffic accident" 1 "There is a traffic accident" 2 "Reserved" 3 "invalid" ;
VAL_ 962 HU_TollInfo 0 "=No toll station" 1 "There is a toll station" 2 "Reserved" 3 "invalid" ;
VAL_ 962 HU_TollDis 0 "0~600m" 61 "Out of Range" 62 "Reserved" 63 "Unknown" ;
VAL_ 962 HU_To_TrafficAccident_Dis 0 "0~600m" 61 "Out of Range" 62 "Reserved" 63 "Unknown" ;
VAL_ 962 HU_To_Construction_Dis 0 "0~600m" 61 "Out of Range" 62 "Reserved" 63 "Unknown" ;
VAL_ 962 HU_To_Branch_Dis 0 "0~600m" 61 "Out of Range" 62 "Reserved" 63 "Unknown" ;
VAL_ 962 HU_Road_TrafficFlow 0 "unknown" 1 "Unblocked" 2 "go slowly" 3 " congestion" 4 "severe congestion" 5 "no traffic flow" 6 "reserved" 7 "invalid" ;
VAL_ 962 HU_RampSide 0 "Unknown" 1 "Left Road" 2 "Right Road" 3 "Invalid" ;
VAL_ 962 HU_MapDataUpdateStatus 0 "Not updated" 1 "Updated within 1 month" 2 "Updated within 3 months" 3 "Updated within 6 months" 4 "Updated within 1 year" 5 " reserved" 7 "Invalid" ;
VAL_ 962 HU_LaneCnt 0 "unknown" 1 "0x1-0x5=Number of current road lanes" 6 "Greater than or equal to 6" 7 "Single-way driving in reverse direction" ;
VAL_ 962 HU_ForwardRoadType 0 "Road Type Unknown£º Small road£¬ Walking Street" 1 "Road Type Class 1£º Secondary Roads" 2 "Road Type Class 2£º Mainly Road in City" 3 "Road Type Class 3£º Mainly Road in City£¬ Normal Province Road£¬ Mainly street" 4 "Road Type Class 4£º Province Road£¬ Mainly Road " 5 "Road Type Class 5£º Highway£¬ National Road£¬ Speed road" 6 "Reserved" 7 "Reserved" ;
VAL_ 962 HU_FallingRockInfo 0 "Path without rocks" 1 "Path has rocks" 2 "Reserved" 3 "invalid" ;
VAL_ 962 HU_FallingRockDi 0 "0~600m" 61 "Out of Range" 62 "Reserved" 63 "Unknown" ;
VAL_ 962 HU_Construction_Info 0 "No construction" 1 "There is construction" 2 "Reserved" 3 "invalid" ;
VAL_ 964 HU_To_NumchangeOfLanes_Dist 0 "0~600m" 61 "Out of Range" 62 "Reserved" 63 "Unknown" ;
VAL_ 964 HU_RoadCurvature_40m 0 " -0.16192 ~ -0.00001,negative number represents curve to left" 8191 " 0,represents straight" 512 " 0.00001 ~ 0.16192,positive number represents curve to right" 1791 " unknown" ;
VAL_ 964 HU_RoadCurvature_30m 0 " -0.16192 ~ -0.00001,negative number represents curve to left" 8191 " 0,represents straight" 512 " 0.00001 ~ 0.16192,positive number represents curve to right" 1791 " unknown" ;
VAL_ 964 HU_RoadCurvature_20m 0 " -0.16192 ~ -0.00001,negative number represents curve to left" 8191 " 0,represents straight" 512 " 0.00001 ~ 0.16192,positive number represents curve to right" 1791 " unknown" ;
VAL_ 964 HU_RoadCurvature_10m 0 " -0.16192 ~ -0.00001,negative number represents curve to left" 8191 " 0,represents straight" 512 " 0.00001 ~ 0.16192,positive number represents curve to right" 1791 " unknown" ;
VAL_ 964 HU_Lane_Changtype 0 "No change£¬0x1=Merge" 2 "Separate£¬
0x3=Invalid" ;
VAL_ 966 HU_RoadCurvature_90m 0 " -0.16192 ~ -0.00001,negative number represents curve to left" 8191 " 0,represents straight" 512 " 0.00001 ~ 0.16192,positive number represents curve to right" 1791 " unknown" ;
VAL_ 966 HU_RoadCurvature_80m 0 " -0.16192 ~ -0.00001,negative number represents curve to left" 8191 " 0,represents straight" 512 " 0.00001 ~ 0.16192,positive number represents curve to right" 1791 " unknown" ;
VAL_ 966 HU_RoadCurvature_70m 0 " -0.16192 ~ -0.00001,negative number represents curve to left" 8191 " 0,represents straight" 512 " 0.00001 ~ 0.16192,positive number represents curve to right" 1791 " unknown" ;
VAL_ 966 HU_RoadCurvature_60m 0 " -0.16192 ~ -0.00001,negative number represents curve to left" 8191 " 0,represents straight" 512 " 0.00001 ~ 0.16192,positive number represents curve to right" 1791 " unknown" ;
VAL_ 966 HU_RoadCurvature_50m 0 " -0.16192 ~ -0.00001,negative number represents curve to left" 8191 " 0,represents straight" 512 " 0.00001 ~ 0.16192,positive number represents curve to right" 1791 " unknown" ;
VAL_ 966 HU_BranchInfo 0 "unknown" 1 "There is a branch, but car does not pass through" 2 "There is a branch, and car passes through" 3 "Reserved" ;
VAL_ 967 HU_SlopeGradient_300m 1023 "Unknown" ;
VAL_ 967 HU_RoadCurvature_600m 0 " -0.16192 ~ -0.00001,negative number represents curve to left" 8191 " 0,represents straight" 512 " 0.00001 ~ 0.16192,positive number represents curve to right" 1791 " unknown" ;
VAL_ 967 HU_RoadCurvature_400m 0 " -0.16192 ~ -0.00001,negative number represents curve to left" 8191 " 0,represents straight" 512 " 0.00001 ~ 0.16192,positive number represents curve to right" 1791 " unknown" ;
VAL_ 967 HU_RoadCurvature_300m 0 " -0.16192 ~ -0.00001,negative number represents curve to left" 8191 " 0,represents straight" 512 " 0.00001 ~ 0.16192,positive number represents curve to right" 1791 " unknown" ;
VAL_ 967 HU_RoadCurvature_100m 0 " -0.16192 ~ -0.00001,negative number represents curve to left" 8191 " 0,represents straight" 512 " 0.00001 ~ 0.16192,positive number represents curve to right" 1791 " unknown" ;
VAL_ 967 HU_MapMatchStatus 0 "Successl" 1 "Fail" 2 "Reserved" 3 "Invalid" ;
VAL_ 999 BCM_T_BATT 146 "Reserved" 255 "Invalid" ;
VAL_ 999 BCM_Status_Temp 0 "No error" 1 "Not used" 2 "HW defect (ADC defect)" 3 "LIN saturation (No HW defect)" ;
VAL_ 1000 BCM_SOF_Q_STATE 0 "deviation > 15%" 1 "deviation <15%" 2 "deviation < 10%" 3 "Invalid" ;
VAL_ 1000 BCM_SOF_Q 255 "Invalid" ;
VAL_ 1023 BCM_RearFoglampStatus 0 "OFF" 1 "ON" 2 "Not used" 3 "Error" ;
VAL_ 1023 BCM_FrontFoglampStatus 0 "OFF" 1 "ON" 2 "Not used" 3 "Reserved" ;
VAL_ 1023 BCM_AutoHeadlightSts 0 "Not Actived" 1 "Actived" ;
VAL_ 80 SRS_WarningLampStatus 0 "Lamp OFF" 1 "Lamp ON" 2 "Lamp Flashing" 3 "Not Used" ;
VAL_ 80 SRS_PassengerBuckleSwitchStatus 0 "Buckled" 1 "Unbuckle " 2 "Not Used" 3 "Not Used
Default value£º0x0" ;
VAL_ 80 SRS_DriverBuckleSwitchStatus 0 "Buckled" 1 "Unbuckle" 2 "Not Used" 3 "Not Used" ;
VAL_ 80 SRS_CrashOutputStatusCheckSum 0 "(SRS_CrashOutputStatus) XOR 0xF" ;
VAL_ 80 SRS_CrashOutputStatus 0 "No Crash" 1 "crash " 2 "Not Used" ;
VAL_ 1280 HU_CurrentLocationValid 0 "Valid" 1 "Not Valid" ;
VAL_ 1280 HU_CurrentLocationLongitude 268435455 "" ;
VAL_ 1280 HU_CurrentLocationLatitude 134217727 "" ;
VAL_ 1281 HU_LocalTimeValid 0 "Valid" 1 "Not Valid" ;
VAL_ 1300 HU_TSRSwitch 0 "OFF" 1 "ON" ;
VAL_ 1300 HU_OverspeedWarningOffset 0 "" 21 "Reserved" 31 "Invalid" ;
VAL_ 1300 HU_OverspeedWarningEnable 0 "Inactive " 1 "OFF" 2 "ON" 3 "Reserved" ;
VAL_ 1300 HU_OverspeedSoundWarEnable 0 "Inactive " 1 "OFF" 2 "ON" 3 "Reserved" ;
VAL_ 1300 HU_LDWShakeLev 0 "Inactive " 1 "Low" 2 "Normal" 3 "High" ;
VAL_ 1300 HU_LASWarningModeSelection 0 "Inactive " 1 "visual" 2 "sound" 3 "vibration" 4 "sound and vibration" 5 "Reserved" ;
VAL_ 1300 HU_LASModeSelection 0 "Inactive " 1 "LDW" 2 "LKA" 3 "LCS" 4 "Reserved" 7 "OFF" ;
VAL_ 1300 HU_IACCEnable 0 "Inactive " 1 "OFF" 2 "ON" 3 "Reserved" ;
VAL_ 1300 HU_HMAEnable 0 "OFF" 1 "ON" ;
